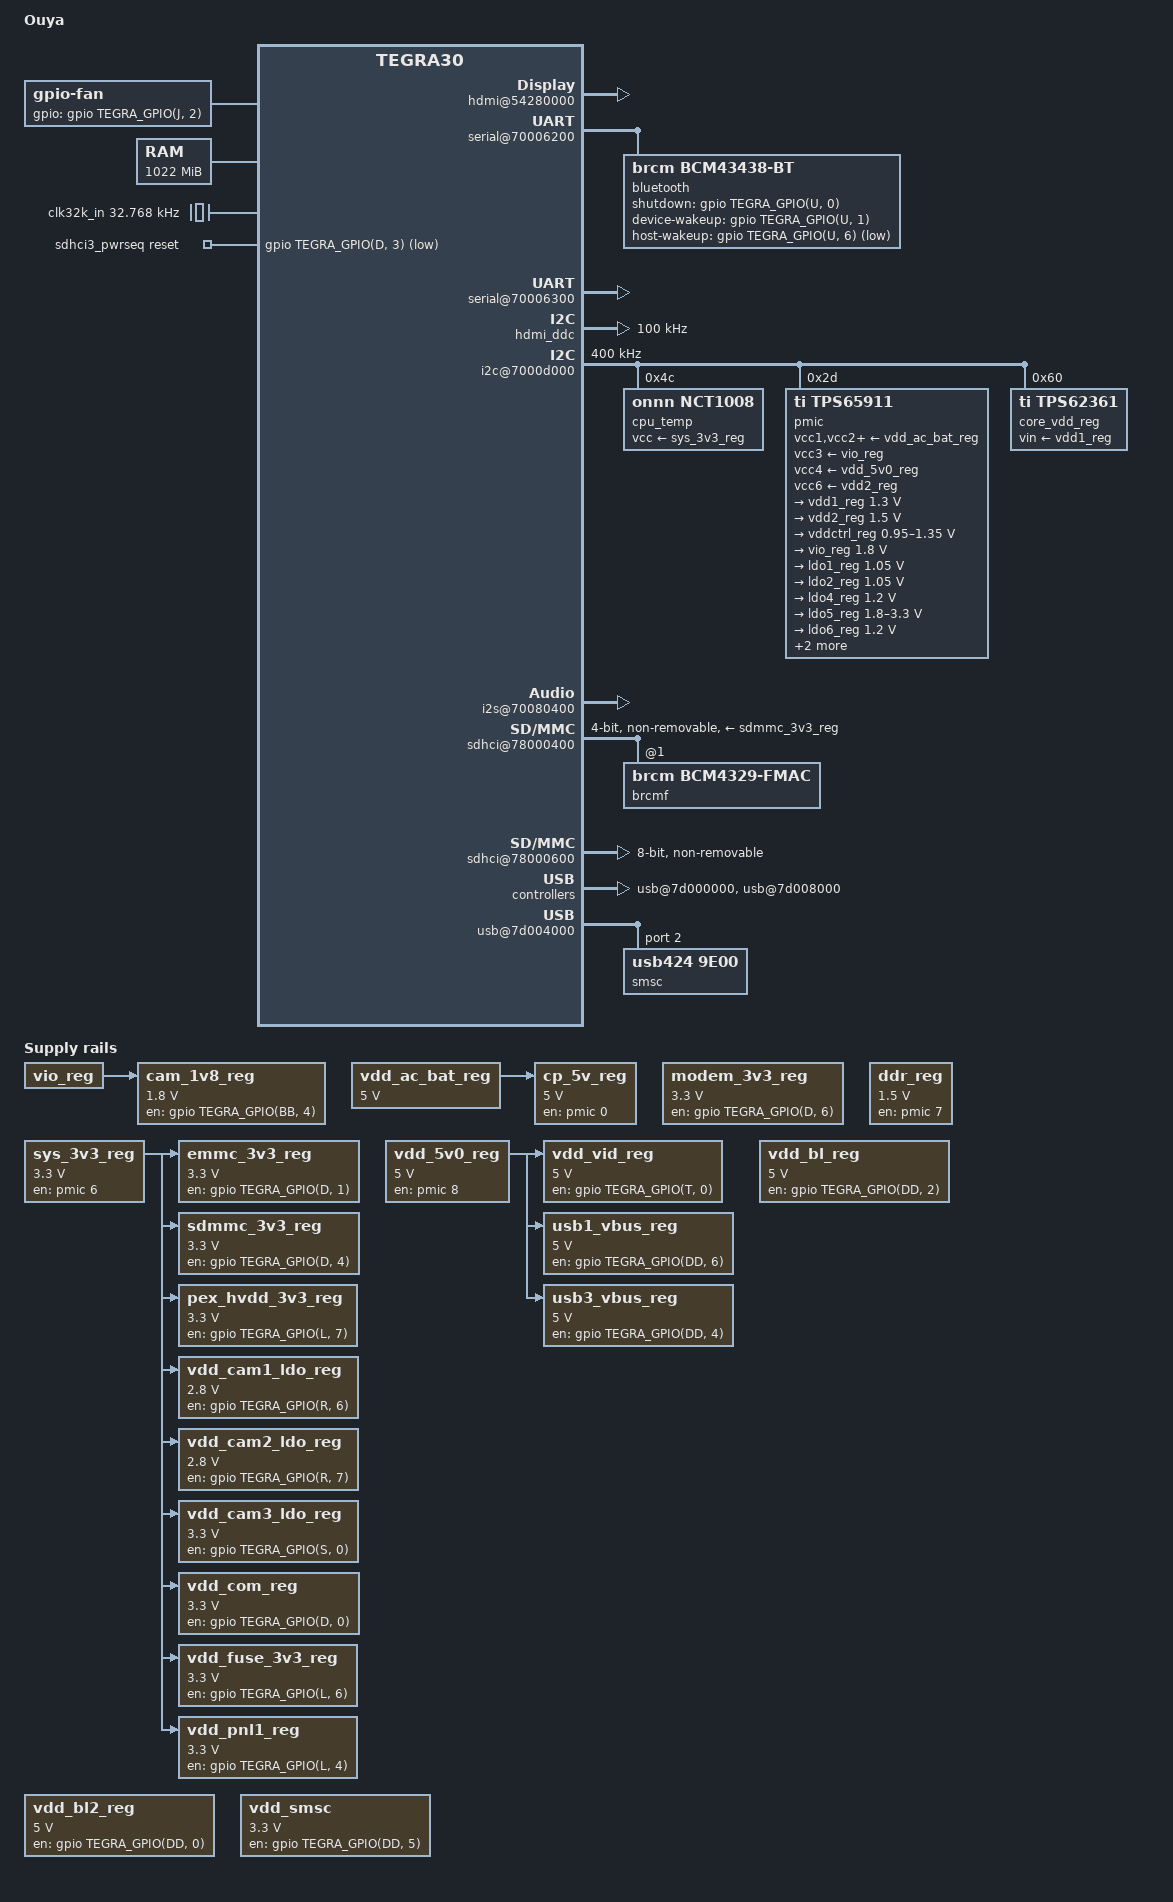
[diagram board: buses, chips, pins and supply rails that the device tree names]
/dts-v1/;

/* This DTS file group supports the OUYA on modern kernels. */
/* The bootloader is extremely basic, and leaves the system in a barely usable state. */
/* This means we have to do everything the bootloader is supposed to do. */

#include <dt-bindings/input/input.h>
#include <dt-bindings/thermal/thermal.h>
#include "tegra30.dtsi"

/ {
	model = "Ouya";
	compatible = "nvidia,ouya", "nvidia,tegra30";

	aliases {
		rtc0 = "/i2c@7000d000/tps65911@2d";
		rtc1 = "/rtc@7000e000";
		serial0 = &uartd;
		serial1 = &uartc;

	};

	chosen {
		stdout-path = "serial0:115200n8";
		bootargs = "earlyprintk gpt gpt_sector=15073279 panic=10 console=ttyS0,115200n8 root=/dev/sda1 rootwait video=HDMI-A-1:1280x720@60 mitigations=off";
	};

	cpus {
		#address-cells = <1>;
		#size-cells = <0>;

		cpu@0 {
			device_type = "cpu";
			compatible = "arm,cortex-a9";
			reg = <0>;
			next-level-cache = <&L2>;
			clock-latency = <65536>; /* two CLK32 periods */
			assigned-clocks = <&tegra_car TEGRA30_CLK_CCLK_G>;
			cpu-supply = <&vddctrl_reg>;
			core-supply = <&core_vdd_reg>;
		};
		cpu@1 {
			next-level-cache = <&L2>;
		};

		cpu@2 {
			next-level-cache = <&L2>;
		};

		cpu@3 {
			next-level-cache = <&L2>;
		};
	};

	fan: gpio_fan {
		compatible = "gpio-fan";
		gpios = <&gpio TEGRA_GPIO(J, 2) GPIO_ACTIVE_HIGH>;
		gpio-fan,speed-map = <0    0
				      4500 1>;
		#cooling-cells = <2>;
	};

	thermal-zones {
		cpu_thermal: cpu-thermal {
			polling-delay = <1000>;
			polling-delay-passive = <250>;

			thermal-sensors = <&cpu_temp 1>;

			trips {
				cpu_alert0: cpu-alert0 {
					temperature = <45000>;
					hysteresis = <5000>;
					type = "active";
				};
				cpu_crit: cpu-crit {
					temperature = <90000>;
					hysteresis = <2000>;
					type = "critical";
				};
			};

			cooling-maps {
				map0 {
					trip = <&cpu_alert0>;
					cooling-device = <&fan 1 THERMAL_NO_LIMIT>;
				};
			};
		};
	};

	L2: cache-controller@50043000 {
	};

	smmu {
		compatible = "nvidia,tegra30-smmu";
		reg = <0x7000f010 0x02c
		       0x7000f1f0 0x010
		       0x7000f228 0x05c>;
		nvidia,#asids = <4>;		/* # of ASIDs */
		dma-window = <0 0x40000000>;	/* IOVA start & length */
		nvidia,ahb = <&ahb>;
	};

	memory@80000000 {
		device_type = "memory";
		reg = <0x80000000 0x3fe00000>;
//		reg = <0x80000000 0x40000000>;
	};

	reserved-memory {
		#address-cells = <1>;
		#size-cells = <1>;
		ranges;

		tf_reserve@7fe00000 {
			reg = <0x7fe00000 0x200000>;
			no-map;
		};
	};

	firmware {
		trusted-foundations {
			compatible = "tlm,trusted-foundations";
			tlm,version-major = <0x2>;
			tlm,version-minor = <0x8>;
		};
	};

	host1x@50000000 {
		hdmi@54280000 {
			status = "okay";
			vdd-supply = <&vdd_vid_reg>;
			pll-supply = <&ldo7_reg>;
			hdmi-supply = <&sys_3v3_reg>;
			nvidia,ddc-i2c-bus = <&hdmi_ddc>;
			nvidia,hpd-gpio = <&gpio TEGRA_GPIO(N, 7) GPIO_ACTIVE_HIGH>;
		};
	};

	gpio: gpio@6000d000 {
		gpio-ranges = <&pinmux 0 0 248>;
		#reset-cells = <1>;
	};

	pinmux@70000868 {
		pinctrl-names = "default";
		pinctrl-0 = <&state_default>;

		state_default: pinmux {
                        clk_32k_out_pa0 {
                                nvidia,pins = "clk_32k_out_pa0";
                                nvidia,function = "blink";
                                nvidia,pull = <TEGRA_PIN_PULL_NONE>;
                                nvidia,tristate = <TEGRA_PIN_DISABLE>;
                                nvidia,enable-input = <TEGRA_PIN_DISABLE>;
                        };
                        uart3_cts_n_pa1 {
                                nvidia,pins = "uart3_cts_n_pa1";
                                nvidia,function = "uartc";
                                nvidia,pull = <TEGRA_PIN_PULL_NONE>;
                                nvidia,tristate = <TEGRA_PIN_DISABLE>;
                                nvidia,enable-input = <TEGRA_PIN_ENABLE>;
                        };
                        dap2_fs_pa2 {
                                nvidia,pins = "dap2_fs_pa2";
                                nvidia,function = "i2s1";
                                nvidia,pull = <TEGRA_PIN_PULL_NONE>;
                                nvidia,tristate = <TEGRA_PIN_DISABLE>;
                                nvidia,enable-input = <TEGRA_PIN_ENABLE>;
                        };
                        dap2_sclk_pa3 {
                                nvidia,pins = "dap2_sclk_pa3";
                                nvidia,function = "i2s1";
                                nvidia,pull = <TEGRA_PIN_PULL_NONE>;
                                nvidia,tristate = <TEGRA_PIN_DISABLE>;
                                nvidia,enable-input = <TEGRA_PIN_ENABLE>;
                        };
                        dap2_din_pa4 {
                                nvidia,pins = "dap2_din_pa4";
                                nvidia,function = "i2s1";
                                nvidia,pull = <TEGRA_PIN_PULL_NONE>;
                                nvidia,tristate = <TEGRA_PIN_DISABLE>;
                                nvidia,enable-input = <TEGRA_PIN_ENABLE>;
                        };
                        dap2_dout_pa5 {
                                nvidia,pins = "dap2_dout_pa5";
                                nvidia,function = "i2s1";
                                nvidia,pull = <TEGRA_PIN_PULL_NONE>;
                                nvidia,tristate = <TEGRA_PIN_DISABLE>;
                                nvidia,enable-input = <TEGRA_PIN_ENABLE>;
                        };
                        sdmmc3_clk_pa6 {
                                nvidia,pins = "sdmmc3_clk_pa6";
                                nvidia,function = "sdmmc3";
                                nvidia,pull = <TEGRA_PIN_PULL_NONE>;
                                nvidia,tristate = <TEGRA_PIN_DISABLE>;
                                nvidia,enable-input = <TEGRA_PIN_ENABLE>;
                        };
                        sdmmc3_cmd_pa7 {
                                nvidia,pins = "sdmmc3_cmd_pa7";
                                nvidia,function = "sdmmc3";
                                nvidia,pull = <TEGRA_PIN_PULL_UP>;
                                nvidia,tristate = <TEGRA_PIN_DISABLE>;
                                nvidia,enable-input = <TEGRA_PIN_ENABLE>;
                        };
                        gmi_a17_pb0 {
                                nvidia,pins = "gmi_a17_pb0";
                                nvidia,function = "spi4";
                                nvidia,pull = <TEGRA_PIN_PULL_NONE>;
                                nvidia,tristate = <TEGRA_PIN_DISABLE>;
                                nvidia,enable-input = <TEGRA_PIN_ENABLE>;
                        };
                        gmi_a18_pb1 {
                                nvidia,pins = "gmi_a18_pb1";
                                nvidia,function = "spi4";
                                nvidia,pull = <TEGRA_PIN_PULL_NONE>;
                                nvidia,tristate = <TEGRA_PIN_DISABLE>;
                                nvidia,enable-input = <TEGRA_PIN_ENABLE>;
                        };
                        lcd_pwr0_pb2 {
                                nvidia,pins = "lcd_pwr0_pb2";
                                nvidia,function = "displaya";
                                nvidia,pull = <TEGRA_PIN_PULL_NONE>;
                                nvidia,tristate = <TEGRA_PIN_DISABLE>;
                                nvidia,enable-input = <TEGRA_PIN_ENABLE>;
                        };
                        lcd_pclk_pb3 {
                                nvidia,pins = "lcd_pclk_pb3";
                                nvidia,function = "displaya";
                                nvidia,pull = <TEGRA_PIN_PULL_NONE>;
                                nvidia,tristate = <TEGRA_PIN_DISABLE>;
                                nvidia,enable-input = <TEGRA_PIN_ENABLE>;
                        };
                        sdmmc3_dat3_pb4 {
                                nvidia,pins = "sdmmc3_dat3_pb4";
                                nvidia,function = "sdmmc3";
                                nvidia,pull = <TEGRA_PIN_PULL_UP>;
                                nvidia,tristate = <TEGRA_PIN_DISABLE>;
                                nvidia,enable-input = <TEGRA_PIN_ENABLE>;
                        };
                        sdmmc3_dat2_pb5 {
                                nvidia,pins = "sdmmc3_dat2_pb5";
                                nvidia,function = "sdmmc3";
                                nvidia,pull = <TEGRA_PIN_PULL_UP>;
                                nvidia,tristate = <TEGRA_PIN_DISABLE>;
                                nvidia,enable-input = <TEGRA_PIN_ENABLE>;
                        };
                        sdmmc3_dat1_pb6 {
                                nvidia,pins = "sdmmc3_dat1_pb6";
                                nvidia,function = "sdmmc3";
                                nvidia,pull = <TEGRA_PIN_PULL_UP>;
                                nvidia,tristate = <TEGRA_PIN_DISABLE>;
                                nvidia,enable-input = <TEGRA_PIN_ENABLE>;
                        };
                        sdmmc3_dat0_pb7 {
                                nvidia,pins = "sdmmc3_dat0_pb7";
                                nvidia,function = "sdmmc3";
                                nvidia,pull = <TEGRA_PIN_PULL_UP>;
                                nvidia,tristate = <TEGRA_PIN_DISABLE>;
                                nvidia,enable-input = <TEGRA_PIN_ENABLE>;
                        };
                        uart3_rts_n_pc0 {
                                nvidia,pins = "uart3_rts_n_pc0";
                                nvidia,function = "uartc";
                                nvidia,pull = <TEGRA_PIN_PULL_NONE>;
                                nvidia,tristate = <TEGRA_PIN_DISABLE>;
                                nvidia,enable-input = <TEGRA_PIN_DISABLE>;
                        };
                        lcd_pwr1_pc1 {
                                nvidia,pins = "lcd_pwr1_pc1";
                                nvidia,function = "displaya";
                                nvidia,pull = <TEGRA_PIN_PULL_NONE>;
                                nvidia,tristate = <TEGRA_PIN_DISABLE>;
                                nvidia,enable-input = <TEGRA_PIN_ENABLE>;
                        };
                        uart2_txd_pc2 {
                                nvidia,pins = "uart2_txd_pc2";
                                nvidia,function = "uartb";
                                nvidia,pull = <TEGRA_PIN_PULL_NONE>;
                                nvidia,tristate = <TEGRA_PIN_DISABLE>;
                                nvidia,enable-input = <TEGRA_PIN_DISABLE>;
                        };
                        uart2_rxd_pc3 {
                                nvidia,pins = "uart2_rxd_pc3";
                                nvidia,function = "uartb";
                                nvidia,pull = <TEGRA_PIN_PULL_NONE>;
                                nvidia,tristate = <TEGRA_PIN_DISABLE>;
                                nvidia,enable-input = <TEGRA_PIN_ENABLE>;
                        };
                        gen1_i2c_scl_pc4 {
                                nvidia,pins = "gen1_i2c_scl_pc4";
                                nvidia,function = "i2c1";
                                nvidia,pull = <TEGRA_PIN_PULL_NONE>;
                                nvidia,tristate = <TEGRA_PIN_DISABLE>;
                                nvidia,enable-input = <TEGRA_PIN_ENABLE>;
                                nvidia,open-drain = <TEGRA_PIN_ENABLE>;
                        };
                        gen1_i2c_sda_pc5 {
                                nvidia,pins = "gen1_i2c_sda_pc5";
                                nvidia,function = "i2c1";
                                nvidia,pull = <TEGRA_PIN_PULL_NONE>;
                                nvidia,tristate = <TEGRA_PIN_DISABLE>;
                                nvidia,enable-input = <TEGRA_PIN_ENABLE>;
                                nvidia,open-drain = <TEGRA_PIN_ENABLE>;
                        };
                        lcd_pwr2_pc6 {
                                nvidia,pins = "lcd_pwr2_pc6";
                                nvidia,function = "displaya";
                                nvidia,pull = <TEGRA_PIN_PULL_NONE>;
                                nvidia,tristate = <TEGRA_PIN_DISABLE>;
                                nvidia,enable-input = <TEGRA_PIN_ENABLE>;
                        };
                        gmi_wp_n_pc7 {
                                nvidia,pins = "gmi_wp_n_pc7";
                                nvidia,function = "gmi";
                                nvidia,pull = <TEGRA_PIN_PULL_NONE>;
                                nvidia,tristate = <TEGRA_PIN_DISABLE>;
                                nvidia,enable-input = <TEGRA_PIN_ENABLE>;
                        };
                        sdmmc3_dat5_pd0 {
                                nvidia,pins = "sdmmc3_dat5_pd0";
                                nvidia,function = "sdmmc3";
                                nvidia,pull = <TEGRA_PIN_PULL_UP>;
                                nvidia,tristate = <TEGRA_PIN_DISABLE>;
                                nvidia,enable-input = <TEGRA_PIN_ENABLE>;
                        };
                        sdmmc3_dat4_pd1 {
                                nvidia,pins = "sdmmc3_dat4_pd1";
                                nvidia,function = "sdmmc3";
                                nvidia,pull = <TEGRA_PIN_PULL_UP>;
                                nvidia,tristate = <TEGRA_PIN_DISABLE>;
                                nvidia,enable-input = <TEGRA_PIN_ENABLE>;
                        };
                        lcd_dc1_pd2 {
                                nvidia,pins = "lcd_dc1_pd2";
                                nvidia,function = "displaya";
                                nvidia,pull = <TEGRA_PIN_PULL_NONE>;
                                nvidia,tristate = <TEGRA_PIN_DISABLE>;
                                nvidia,enable-input = <TEGRA_PIN_ENABLE>;
                        };
                        sdmmc3_dat6_pd3 {
                                nvidia,pins = "sdmmc3_dat6_pd3";
                                nvidia,function = "spdif";
                                nvidia,pull = <TEGRA_PIN_PULL_NONE>;
                                nvidia,tristate = <TEGRA_PIN_DISABLE>;
                                nvidia,enable-input = <TEGRA_PIN_ENABLE>;
                        };
                        sdmmc3_dat7_pd4 {
                                nvidia,pins = "sdmmc3_dat7_pd4";
                                nvidia,function = "spdif";
                                nvidia,pull = <TEGRA_PIN_PULL_NONE>;
                                nvidia,tristate = <TEGRA_PIN_DISABLE>;
                                nvidia,enable-input = <TEGRA_PIN_ENABLE>;
                        };
                        vi_d1_pd5 {
                                nvidia,pins = "vi_d1_pd5";
                                nvidia,function = "sdmmc2";
                                nvidia,pull = <TEGRA_PIN_PULL_NONE>;
                                nvidia,tristate = <TEGRA_PIN_DISABLE>;
                                nvidia,enable-input = <TEGRA_PIN_ENABLE>;
                        };
                        vi_vsync_pd6 {
                                nvidia,pins = "vi_vsync_pd6";
                                nvidia,function = "ddr";
                                nvidia,pull = <TEGRA_PIN_PULL_NONE>;
                                nvidia,tristate = <TEGRA_PIN_DISABLE>;
                                nvidia,enable-input = <TEGRA_PIN_ENABLE>;
                        };
                        vi_hsync_pd7 {
                                nvidia,pins = "vi_hsync_pd7";
                                nvidia,function = "ddr";
                                nvidia,pull = <TEGRA_PIN_PULL_NONE>;
                                nvidia,tristate = <TEGRA_PIN_DISABLE>;
                                nvidia,enable-input = <TEGRA_PIN_ENABLE>;
                        };
                        lcd_d0_pe0 {
                                nvidia,pins = "lcd_d0_pe0";
                                nvidia,function = "displaya";
                                nvidia,pull = <TEGRA_PIN_PULL_NONE>;
                                nvidia,tristate = <TEGRA_PIN_DISABLE>;
                                nvidia,enable-input = <TEGRA_PIN_ENABLE>;
                        };
                        lcd_d1_pe1 {
                                nvidia,pins = "lcd_d1_pe1";
                                nvidia,function = "displaya";
                                nvidia,pull = <TEGRA_PIN_PULL_NONE>;
                                nvidia,tristate = <TEGRA_PIN_DISABLE>;
                                nvidia,enable-input = <TEGRA_PIN_ENABLE>;
                        };
                        lcd_d2_pe2 {
                                nvidia,pins = "lcd_d2_pe2";
                                nvidia,function = "displaya";
                                nvidia,pull = <TEGRA_PIN_PULL_NONE>;
                                nvidia,tristate = <TEGRA_PIN_DISABLE>;
                                nvidia,enable-input = <TEGRA_PIN_ENABLE>;
                        };
                        lcd_d3_pe3 {
                                nvidia,pins = "lcd_d3_pe3";
                                nvidia,function = "displaya";
                                nvidia,pull = <TEGRA_PIN_PULL_NONE>;
                                nvidia,tristate = <TEGRA_PIN_DISABLE>;
                                nvidia,enable-input = <TEGRA_PIN_ENABLE>;
                        };
                        lcd_d4_pe4 {
                                nvidia,pins = "lcd_d4_pe4";
                                nvidia,function = "displaya";
                                nvidia,pull = <TEGRA_PIN_PULL_NONE>;
                                nvidia,tristate = <TEGRA_PIN_DISABLE>;
                                nvidia,enable-input = <TEGRA_PIN_ENABLE>;
                        };
                        lcd_d5_pe5 {
                                nvidia,pins = "lcd_d5_pe5";
                                nvidia,function = "displaya";
                                nvidia,pull = <TEGRA_PIN_PULL_NONE>;
                                nvidia,tristate = <TEGRA_PIN_DISABLE>;
                                nvidia,enable-input = <TEGRA_PIN_ENABLE>;
                        };
                        lcd_d6_pe6 {
                                nvidia,pins = "lcd_d6_pe6";
                                nvidia,function = "displaya";
                                nvidia,pull = <TEGRA_PIN_PULL_NONE>;
                                nvidia,tristate = <TEGRA_PIN_DISABLE>;
                                nvidia,enable-input = <TEGRA_PIN_ENABLE>;
                        };
                        lcd_d7_pe7 {
                                nvidia,pins = "lcd_d7_pe7";
                                nvidia,function = "displaya";
                                nvidia,pull = <TEGRA_PIN_PULL_NONE>;
                                nvidia,tristate = <TEGRA_PIN_DISABLE>;
                                nvidia,enable-input = <TEGRA_PIN_ENABLE>;
                        };
                        lcd_d8_pf0 {
                                nvidia,pins = "lcd_d8_pf0";
                                nvidia,function = "displaya";
                                nvidia,pull = <TEGRA_PIN_PULL_NONE>;
                                nvidia,tristate = <TEGRA_PIN_DISABLE>;
                                nvidia,enable-input = <TEGRA_PIN_ENABLE>;
                        };
                        lcd_d9_pf1 {
                                nvidia,pins = "lcd_d9_pf1";
                                nvidia,function = "displaya";
                                nvidia,pull = <TEGRA_PIN_PULL_NONE>;
                                nvidia,tristate = <TEGRA_PIN_DISABLE>;
                                nvidia,enable-input = <TEGRA_PIN_ENABLE>;
                        };
                        lcd_d10_pf2 {
                                nvidia,pins = "lcd_d10_pf2";
                                nvidia,function = "displaya";
                                nvidia,pull = <TEGRA_PIN_PULL_NONE>;
                                nvidia,tristate = <TEGRA_PIN_DISABLE>;
                                nvidia,enable-input = <TEGRA_PIN_ENABLE>;
                        };
                        lcd_d11_pf3 {
                                nvidia,pins = "lcd_d11_pf3";
                                nvidia,function = "displaya";
                                nvidia,pull = <TEGRA_PIN_PULL_NONE>;
                                nvidia,tristate = <TEGRA_PIN_DISABLE>;
                                nvidia,enable-input = <TEGRA_PIN_ENABLE>;
                        };
                        lcd_d12_pf4 {
                                nvidia,pins = "lcd_d12_pf4";
                                nvidia,function = "displaya";
                                nvidia,pull = <TEGRA_PIN_PULL_NONE>;
                                nvidia,tristate = <TEGRA_PIN_DISABLE>;
                                nvidia,enable-input = <TEGRA_PIN_ENABLE>;
                        };
                        lcd_d13_pf5 {
                                nvidia,pins = "lcd_d13_pf5";
                                nvidia,function = "displaya";
                                nvidia,pull = <TEGRA_PIN_PULL_NONE>;
                                nvidia,tristate = <TEGRA_PIN_DISABLE>;
                                nvidia,enable-input = <TEGRA_PIN_ENABLE>;
                        };
                        lcd_d14_pf6 {
                                nvidia,pins = "lcd_d14_pf6";
                                nvidia,function = "displaya";
                                nvidia,pull = <TEGRA_PIN_PULL_NONE>;
                                nvidia,tristate = <TEGRA_PIN_DISABLE>;
                                nvidia,enable-input = <TEGRA_PIN_ENABLE>;
                        };
                        lcd_d15_pf7 {
                                nvidia,pins = "lcd_d15_pf7";
                                nvidia,function = "displaya";
                                nvidia,pull = <TEGRA_PIN_PULL_NONE>;
                                nvidia,tristate = <TEGRA_PIN_DISABLE>;
                                nvidia,enable-input = <TEGRA_PIN_ENABLE>;
                        };
                        gmi_ad0_pg0 {
                                nvidia,pins = "gmi_ad0_pg0";
                                nvidia,function = "nand";
                                nvidia,pull = <TEGRA_PIN_PULL_NONE>;
                                nvidia,tristate = <TEGRA_PIN_ENABLE>;
                                nvidia,enable-input = <TEGRA_PIN_DISABLE>;
                        };
                        gmi_ad1_pg1 {
                                nvidia,pins = "gmi_ad1_pg1";
                                nvidia,function = "nand";
                                nvidia,pull = <TEGRA_PIN_PULL_NONE>;
                                nvidia,tristate = <TEGRA_PIN_ENABLE>;
                                nvidia,enable-input = <TEGRA_PIN_DISABLE>;
                        };
                        gmi_ad2_pg2 {
                                nvidia,pins = "gmi_ad2_pg2";
                                nvidia,function = "nand";
                                nvidia,pull = <TEGRA_PIN_PULL_NONE>;
                                nvidia,tristate = <TEGRA_PIN_ENABLE>;
                                nvidia,enable-input = <TEGRA_PIN_DISABLE>;
                        };
                        gmi_ad3_pg3 {
                                nvidia,pins = "gmi_ad3_pg3";
                                nvidia,function = "nand";
                                nvidia,pull = <TEGRA_PIN_PULL_NONE>;
                                nvidia,tristate = <TEGRA_PIN_ENABLE>;
                                nvidia,enable-input = <TEGRA_PIN_DISABLE>;
                        };
                        gmi_ad4_pg4 {
                                nvidia,pins = "gmi_ad4_pg4";
                                nvidia,function = "nand";
                                nvidia,pull = <TEGRA_PIN_PULL_NONE>;
                                nvidia,tristate = <TEGRA_PIN_ENABLE>;
                                nvidia,enable-input = <TEGRA_PIN_DISABLE>;
                        };
                        gmi_ad5_pg5 {
                                nvidia,pins = "gmi_ad5_pg5";
                                nvidia,function = "nand";
                                nvidia,pull = <TEGRA_PIN_PULL_NONE>;
                                nvidia,tristate = <TEGRA_PIN_ENABLE>;
                                nvidia,enable-input = <TEGRA_PIN_DISABLE>;
                        };
                        gmi_ad6_pg6 {
                                nvidia,pins = "gmi_ad6_pg6";
                                nvidia,function = "nand";
                                nvidia,pull = <TEGRA_PIN_PULL_NONE>;
                                nvidia,tristate = <TEGRA_PIN_ENABLE>;
                                nvidia,enable-input = <TEGRA_PIN_DISABLE>;
                        };
                        gmi_ad7_pg7 {
                                nvidia,pins = "gmi_ad7_pg7";
                                nvidia,function = "nand";
                                nvidia,pull = <TEGRA_PIN_PULL_NONE>;
                                nvidia,tristate = <TEGRA_PIN_ENABLE>;
                                nvidia,enable-input = <TEGRA_PIN_DISABLE>;
                        };
                        gmi_ad8_ph0 {
                                nvidia,pins = "gmi_ad8_ph0";
                                nvidia,function = "pwm0";
                                nvidia,pull = <TEGRA_PIN_PULL_NONE>;
                                nvidia,tristate = <TEGRA_PIN_DISABLE>;
                                nvidia,enable-input = <TEGRA_PIN_DISABLE>;
                        };
                        gmi_ad9_ph1 {
                                nvidia,pins = "gmi_ad9_ph1";
                                nvidia,function = "pwm1";
                                nvidia,pull = <TEGRA_PIN_PULL_NONE>;
                                nvidia,tristate = <TEGRA_PIN_ENABLE>;
                                nvidia,enable-input = <TEGRA_PIN_DISABLE>;
                        };
                        gmi_ad10_ph2 {
                                nvidia,pins = "gmi_ad10_ph2";
                                nvidia,function = "nand";
                                nvidia,pull = <TEGRA_PIN_PULL_NONE>;
                                nvidia,tristate = <TEGRA_PIN_DISABLE>;
                                nvidia,enable-input = <TEGRA_PIN_DISABLE>;
                        };
                        gmi_ad11_ph3 {
                                nvidia,pins = "gmi_ad11_ph3";
                                nvidia,function = "nand";
                                nvidia,pull = <TEGRA_PIN_PULL_NONE>;
                                nvidia,tristate = <TEGRA_PIN_ENABLE>;
                                nvidia,enable-input = <TEGRA_PIN_DISABLE>;
                        };
                        gmi_ad12_ph4 {
                                nvidia,pins = "gmi_ad12_ph4";
                                nvidia,function = "nand";
                                nvidia,pull = <TEGRA_PIN_PULL_UP>;
                                nvidia,tristate = <TEGRA_PIN_DISABLE>;
                                nvidia,enable-input = <TEGRA_PIN_ENABLE>;
                        };
                        gmi_ad13_ph5 {
                                nvidia,pins = "gmi_ad13_ph5";
                                nvidia,function = "nand";
                                nvidia,pull = <TEGRA_PIN_PULL_UP>;
                                nvidia,tristate = <TEGRA_PIN_ENABLE>;
                                nvidia,enable-input = <TEGRA_PIN_ENABLE>;
                        };
                        gmi_ad14_ph6 {
                                nvidia,pins = "gmi_ad14_ph6";
                                nvidia,function = "nand";
                                nvidia,pull = <TEGRA_PIN_PULL_NONE>;
                                nvidia,tristate = <TEGRA_PIN_DISABLE>;
                                nvidia,enable-input = <TEGRA_PIN_DISABLE>;
                        };
                        gmi_wr_n_pi0 {
                                nvidia,pins = "gmi_wr_n_pi0";
                                nvidia,function = "nand";
                                nvidia,pull = <TEGRA_PIN_PULL_NONE>;
                                nvidia,tristate = <TEGRA_PIN_ENABLE>;
                                nvidia,enable-input = <TEGRA_PIN_DISABLE>;
                        };
                        gmi_oe_n_pi1 {
                                nvidia,pins = "gmi_oe_n_pi1";
                                nvidia,function = "nand";
                                nvidia,pull = <TEGRA_PIN_PULL_NONE>;
                                nvidia,tristate = <TEGRA_PIN_ENABLE>;
                                nvidia,enable-input = <TEGRA_PIN_DISABLE>;
                        };
                        gmi_dqs_pi2 {
                                nvidia,pins = "gmi_dqs_pi2";
                                nvidia,function = "nand";
                                nvidia,pull = <TEGRA_PIN_PULL_NONE>;
                                nvidia,tristate = <TEGRA_PIN_ENABLE>;
                                nvidia,enable-input = <TEGRA_PIN_DISABLE>;
                        };
                        gmi_iordy_pi5 {
                                nvidia,pins = "gmi_iordy_pi5";
                                nvidia,function = "rsvd1";
                                nvidia,pull = <TEGRA_PIN_PULL_UP>;
                                nvidia,tristate = <TEGRA_PIN_DISABLE>;
                                nvidia,enable-input = <TEGRA_PIN_ENABLE>;
                        };
                        gmi_cs7_n_pi6 {
                                nvidia,pins = "gmi_cs7_n_pi6";
                                nvidia,function = "nand";
                                nvidia,pull = <TEGRA_PIN_PULL_UP>;
                                nvidia,tristate = <TEGRA_PIN_ENABLE>;
                                nvidia,enable-input = <TEGRA_PIN_ENABLE>;
                        };
                        gmi_wait_pi7 {
                                nvidia,pins = "gmi_wait_pi7";
                                nvidia,function = "nand";
                                nvidia,pull = <TEGRA_PIN_PULL_UP>;
                                nvidia,tristate = <TEGRA_PIN_ENABLE>;
                                nvidia,enable-input = <TEGRA_PIN_DISABLE>;
                        };
                        lcd_de_pj1 {
                                nvidia,pins = "lcd_de_pj1";
                                nvidia,function = "displaya";
                                nvidia,pull = <TEGRA_PIN_PULL_NONE>;
                                nvidia,tristate = <TEGRA_PIN_DISABLE>;
                                nvidia,enable-input = <TEGRA_PIN_ENABLE>;
                        };
			gmi_cs1_n_pj2 {
                                nvidia,pins = "gmi_cs1_n_pj2";
                                nvidia,function = "rsvd1";
                                nvidia,pull = <TEGRA_PIN_PULL_NONE>;
                                nvidia,tristate = <TEGRA_PIN_DISABLE>;
                                nvidia,enable-input = <TEGRA_PIN_DISABLE>;
                        };
                        lcd_hsync_pj3 {
                                nvidia,pins = "lcd_hsync_pj3";
                                nvidia,function = "displaya";
                                nvidia,pull = <TEGRA_PIN_PULL_NONE>;
                                nvidia,tristate = <TEGRA_PIN_DISABLE>;
                                nvidia,enable-input = <TEGRA_PIN_ENABLE>;
                        };
                        lcd_vsync_pj4 {
                                nvidia,pins = "lcd_vsync_pj4";
                                nvidia,function = "displaya";
                                nvidia,pull = <TEGRA_PIN_PULL_NONE>;
                                nvidia,tristate = <TEGRA_PIN_DISABLE>;
                                nvidia,enable-input = <TEGRA_PIN_ENABLE>;
                        };
                        uart2_cts_n_pj5 {
                                nvidia,pins = "uart2_cts_n_pj5";
                                nvidia,function = "uartb";
                                nvidia,pull = <TEGRA_PIN_PULL_NONE>;
                                nvidia,tristate = <TEGRA_PIN_DISABLE>;
                                nvidia,enable-input = <TEGRA_PIN_ENABLE>;
                        };
                        uart2_rts_n_pj6 {
                                nvidia,pins = "uart2_rts_n_pj6";
                                nvidia,function = "uartb";
                                nvidia,pull = <TEGRA_PIN_PULL_NONE>;
                                nvidia,tristate = <TEGRA_PIN_DISABLE>;
                                nvidia,enable-input = <TEGRA_PIN_DISABLE>;
                        };
                        gmi_a16_pj7 {
                                nvidia,pins = "gmi_a16_pj7";
                                nvidia,function = "spi4";
                                nvidia,pull = <TEGRA_PIN_PULL_NONE>;
                                nvidia,tristate = <TEGRA_PIN_DISABLE>;
                                nvidia,enable-input = <TEGRA_PIN_ENABLE>;
                        };
                        gmi_adv_n_pk0 {
                                nvidia,pins = "gmi_adv_n_pk0";
                                nvidia,function = "nand";
                                nvidia,pull = <TEGRA_PIN_PULL_NONE>;
                                nvidia,tristate = <TEGRA_PIN_ENABLE>;
                                nvidia,enable-input = <TEGRA_PIN_DISABLE>;
                        };
                        gmi_clk_pk1 {
                                nvidia,pins = "gmi_clk_pk1";
                                nvidia,function = "nand";
                                nvidia,pull = <TEGRA_PIN_PULL_NONE>;
                                nvidia,tristate = <TEGRA_PIN_ENABLE>;
                                nvidia,enable-input = <TEGRA_PIN_DISABLE>;
                        };
                        gmi_cs2_n_pk3 {
                                nvidia,pins = "gmi_cs2_n_pk3";
                                nvidia,function = "rsvd1";
                                nvidia,pull = <TEGRA_PIN_PULL_UP>;
                                nvidia,tristate = <TEGRA_PIN_DISABLE>;
                                nvidia,enable-input = <TEGRA_PIN_ENABLE>;
                        };
                        gmi_cs3_n_pk4 {
                                nvidia,pins = "gmi_cs3_n_pk4";
                                nvidia,function = "nand";
                                nvidia,pull = <TEGRA_PIN_PULL_NONE>;
                                nvidia,tristate = <TEGRA_PIN_ENABLE>;
                                nvidia,enable-input = <TEGRA_PIN_DISABLE>;
                        };
                        spdif_out_pk5 {
                                nvidia,pins = "spdif_out_pk5";
                                nvidia,function = "spdif";
                                nvidia,pull = <TEGRA_PIN_PULL_NONE>;
                                nvidia,tristate = <TEGRA_PIN_DISABLE>;
                                nvidia,enable-input = <TEGRA_PIN_DISABLE>;
                        };
                        spdif_in_pk6 {
                                nvidia,pins = "spdif_in_pk6";
                                nvidia,function = "spdif";
                                nvidia,pull = <TEGRA_PIN_PULL_NONE>;
                                nvidia,tristate = <TEGRA_PIN_DISABLE>;
                                nvidia,enable-input = <TEGRA_PIN_ENABLE>;
                        };
                        gmi_a19_pk7 {
                                nvidia,pins = "gmi_a19_pk7";
                                nvidia,function = "spi4";
                                nvidia,pull = <TEGRA_PIN_PULL_NONE>;
                                nvidia,tristate = <TEGRA_PIN_DISABLE>;
                                nvidia,enable-input = <TEGRA_PIN_ENABLE>;
                        };
                        vi_d2_pl0 {
                                nvidia,pins = "vi_d2_pl0";
                                nvidia,function = "sdmmc2";
                                nvidia,pull = <TEGRA_PIN_PULL_NONE>;
                                nvidia,tristate = <TEGRA_PIN_DISABLE>;
                                nvidia,enable-input = <TEGRA_PIN_ENABLE>;
                        };
                        vi_d3_pl1 {
                                nvidia,pins = "vi_d3_pl1";
                                nvidia,function = "sdmmc2";
                                nvidia,pull = <TEGRA_PIN_PULL_NONE>;
                                nvidia,tristate = <TEGRA_PIN_DISABLE>;
                                nvidia,enable-input = <TEGRA_PIN_ENABLE>;
                        };
                        vi_d4_pl2 {
                                nvidia,pins = "vi_d4_pl2";
                                nvidia,function = "vi";
                                nvidia,pull = <TEGRA_PIN_PULL_NONE>;
                                nvidia,tristate = <TEGRA_PIN_DISABLE>;
                                nvidia,enable-input = <TEGRA_PIN_DISABLE>;
                        };
                        vi_d5_pl3 {
                                nvidia,pins = "vi_d5_pl3";
                                nvidia,function = "sdmmc2";
                                nvidia,pull = <TEGRA_PIN_PULL_NONE>;
                                nvidia,tristate = <TEGRA_PIN_DISABLE>;
                                nvidia,enable-input = <TEGRA_PIN_ENABLE>;
                        };
                        vi_d6_pl4 {
                                nvidia,pins = "vi_d6_pl4";
                                nvidia,function = "vi";
                                nvidia,pull = <TEGRA_PIN_PULL_NONE>;
                                nvidia,tristate = <TEGRA_PIN_DISABLE>;
                                nvidia,enable-input = <TEGRA_PIN_DISABLE>;
                        };
                        vi_d7_pl5 {
                                nvidia,pins = "vi_d7_pl5";
                                nvidia,function = "sdmmc2";
                                nvidia,pull = <TEGRA_PIN_PULL_NONE>;
                                nvidia,tristate = <TEGRA_PIN_DISABLE>;
                                nvidia,enable-input = <TEGRA_PIN_ENABLE>;
                        };
                        vi_d8_pl6 {
                                nvidia,pins = "vi_d8_pl6";
                                nvidia,function = "sdmmc2";
                                nvidia,pull = <TEGRA_PIN_PULL_NONE>;
                                nvidia,tristate = <TEGRA_PIN_DISABLE>;
                                nvidia,enable-input = <TEGRA_PIN_ENABLE>;
                        };
                        vi_d9_pl7 {
                                nvidia,pins = "vi_d9_pl7";
                                nvidia,function = "sdmmc2";
                                nvidia,pull = <TEGRA_PIN_PULL_NONE>;
                                nvidia,tristate = <TEGRA_PIN_DISABLE>;
                                nvidia,enable-input = <TEGRA_PIN_ENABLE>;
                        };
                        lcd_d16_pm0 {
                                nvidia,pins = "lcd_d16_pm0";
                                nvidia,function = "displaya";
                                nvidia,pull = <TEGRA_PIN_PULL_NONE>;
                                nvidia,tristate = <TEGRA_PIN_DISABLE>;
                                nvidia,enable-input = <TEGRA_PIN_ENABLE>;
                        };
                        lcd_d17_pm1 {
                                nvidia,pins = "lcd_d17_pm1";
                                nvidia,function = "displaya";
                                nvidia,pull = <TEGRA_PIN_PULL_NONE>;
                                nvidia,tristate = <TEGRA_PIN_DISABLE>;
                                nvidia,enable-input = <TEGRA_PIN_ENABLE>;
                        };
                        lcd_d18_pm2 {
                                nvidia,pins = "lcd_d18_pm2";
                                nvidia,function = "displaya";
                                nvidia,pull = <TEGRA_PIN_PULL_NONE>;
                                nvidia,tristate = <TEGRA_PIN_DISABLE>;
                                nvidia,enable-input = <TEGRA_PIN_ENABLE>;
                        };
                        lcd_d19_pm3 {
                                nvidia,pins = "lcd_d19_pm3";
                                nvidia,function = "displaya";
                                nvidia,pull = <TEGRA_PIN_PULL_NONE>;
                                nvidia,tristate = <TEGRA_PIN_DISABLE>;
                                nvidia,enable-input = <TEGRA_PIN_ENABLE>;
                        };
                        lcd_d20_pm4 {
                                nvidia,pins = "lcd_d20_pm4";
                                nvidia,function = "displaya";
                                nvidia,pull = <TEGRA_PIN_PULL_NONE>;
                                nvidia,tristate = <TEGRA_PIN_DISABLE>;
                                nvidia,enable-input = <TEGRA_PIN_ENABLE>;
                        };
                        lcd_d21_pm5 {
                                nvidia,pins = "lcd_d21_pm5";
                                nvidia,function = "displaya";
                                nvidia,pull = <TEGRA_PIN_PULL_NONE>;
                                nvidia,tristate = <TEGRA_PIN_DISABLE>;
                                nvidia,enable-input = <TEGRA_PIN_ENABLE>;
                        };
                        lcd_d22_pm6 {
                                nvidia,pins = "lcd_d22_pm6";
                                nvidia,function = "displaya";
                                nvidia,pull = <TEGRA_PIN_PULL_NONE>;
                                nvidia,tristate = <TEGRA_PIN_DISABLE>;
                                nvidia,enable-input = <TEGRA_PIN_ENABLE>;
                        };
                        lcd_d23_pm7 {
                                nvidia,pins = "lcd_d23_pm7";
                                nvidia,function = "displaya";
                                nvidia,pull = <TEGRA_PIN_PULL_NONE>;
                                nvidia,tristate = <TEGRA_PIN_DISABLE>;
                                nvidia,enable-input = <TEGRA_PIN_ENABLE>;
                        };
                        dap1_fs_pn0 {
                                nvidia,pins = "dap1_fs_pn0";
                                nvidia,function = "i2s0";
                                nvidia,pull = <TEGRA_PIN_PULL_NONE>;
                                nvidia,tristate = <TEGRA_PIN_DISABLE>;
                                nvidia,enable-input = <TEGRA_PIN_ENABLE>;
                        };
                        dap1_din_pn1 {
                                nvidia,pins = "dap1_din_pn1";
                                nvidia,function = "i2s0";
                                nvidia,pull = <TEGRA_PIN_PULL_NONE>;
                                nvidia,tristate = <TEGRA_PIN_DISABLE>;
                                nvidia,enable-input = <TEGRA_PIN_ENABLE>;
                        };
                        dap1_dout_pn2 {
                                nvidia,pins = "dap1_dout_pn2";
                                nvidia,function = "i2s0";
                                nvidia,pull = <TEGRA_PIN_PULL_NONE>;
                                nvidia,tristate = <TEGRA_PIN_DISABLE>;
                                nvidia,enable-input = <TEGRA_PIN_ENABLE>;
                        };
                        dap1_sclk_pn3 {
                                nvidia,pins = "dap1_sclk_pn3";
                                nvidia,function = "i2s0";
                                nvidia,pull = <TEGRA_PIN_PULL_NONE>;
                                nvidia,tristate = <TEGRA_PIN_DISABLE>;
                                nvidia,enable-input = <TEGRA_PIN_ENABLE>;
                        };
                        lcd_cs0_n_pn4 {
                                nvidia,pins = "lcd_cs0_n_pn4";
                                nvidia,function = "displaya";
                                nvidia,pull = <TEGRA_PIN_PULL_NONE>;
                                nvidia,tristate = <TEGRA_PIN_DISABLE>;
                                nvidia,enable-input = <TEGRA_PIN_ENABLE>;
                        };
                        lcd_sdout_pn5 {
                                nvidia,pins = "lcd_sdout_pn5";
                                nvidia,function = "displaya";
                                nvidia,pull = <TEGRA_PIN_PULL_NONE>;
                                nvidia,tristate = <TEGRA_PIN_DISABLE>;
                                nvidia,enable-input = <TEGRA_PIN_ENABLE>;
                        };
                        lcd_dc0_pn6 {
                                nvidia,pins = "lcd_dc0_pn6";
                                nvidia,function = "displaya";
                                nvidia,pull = <TEGRA_PIN_PULL_NONE>;
                                nvidia,tristate = <TEGRA_PIN_DISABLE>;
                                nvidia,enable-input = <TEGRA_PIN_ENABLE>;
                        };
                        hdmi_int_pn7 {
                                nvidia,pins = "hdmi_int_pn7";
                                nvidia,function = "hdmi";
                                nvidia,pull = <TEGRA_PIN_PULL_NONE>;
                                nvidia,tristate = <TEGRA_PIN_ENABLE>;
                                nvidia,enable-input = <TEGRA_PIN_ENABLE>;
                        };
                        ulpi_data7_po0 {
                                nvidia,pins = "ulpi_data7_po0";
                                nvidia,function = "uarta";
                                nvidia,pull = <TEGRA_PIN_PULL_NONE>;
                                nvidia,tristate = <TEGRA_PIN_DISABLE>;
                                nvidia,enable-input = <TEGRA_PIN_DISABLE>;
                        };
                        ulpi_data0_po1 {
                                nvidia,pins = "ulpi_data0_po1";
                                nvidia,function = "uarta";
                                nvidia,pull = <TEGRA_PIN_PULL_NONE>;
                                nvidia,tristate = <TEGRA_PIN_DISABLE>;
                                nvidia,enable-input = <TEGRA_PIN_DISABLE>;
                        };
                        ulpi_data1_po2 {
                                nvidia,pins = "ulpi_data1_po2";
                                nvidia,function = "uarta";
                                nvidia,pull = <TEGRA_PIN_PULL_NONE>;
                                nvidia,tristate = <TEGRA_PIN_DISABLE>;
                                nvidia,enable-input = <TEGRA_PIN_ENABLE>;
                        };
                        ulpi_data2_po3 {
                                nvidia,pins = "ulpi_data2_po3";
                                nvidia,function = "uarta";
                                nvidia,pull = <TEGRA_PIN_PULL_NONE>;
                                nvidia,tristate = <TEGRA_PIN_DISABLE>;
                                nvidia,enable-input = <TEGRA_PIN_ENABLE>;
                        };
                        ulpi_data3_po4 {
                                nvidia,pins = "ulpi_data3_po4";
                                nvidia,function = "uarta";
                                nvidia,pull = <TEGRA_PIN_PULL_NONE>;
                                nvidia,tristate = <TEGRA_PIN_DISABLE>;
                                nvidia,enable-input = <TEGRA_PIN_ENABLE>;
                        };
                        ulpi_data4_po5 {
                                nvidia,pins = "ulpi_data4_po5";
                                nvidia,function = "uarta";
                                nvidia,pull = <TEGRA_PIN_PULL_NONE>;
                                nvidia,tristate = <TEGRA_PIN_DISABLE>;
                                nvidia,enable-input = <TEGRA_PIN_ENABLE>;
                        };
                        ulpi_data5_po6 {
                                nvidia,pins = "ulpi_data5_po6";
                                nvidia,function = "uarta";
                                nvidia,pull = <TEGRA_PIN_PULL_NONE>;
                                nvidia,tristate = <TEGRA_PIN_DISABLE>;
                                nvidia,enable-input = <TEGRA_PIN_ENABLE>;
                        };
                        ulpi_data6_po7 {
                                nvidia,pins = "ulpi_data6_po7";
                                nvidia,function = "uarta";
                                nvidia,pull = <TEGRA_PIN_PULL_NONE>;
                                nvidia,tristate = <TEGRA_PIN_DISABLE>;
                                nvidia,enable-input = <TEGRA_PIN_ENABLE>;
                        };
                        dap3_fs_pp0 {
                                nvidia,pins = "dap3_fs_pp0";
                                nvidia,function = "i2s2";
                                nvidia,pull = <TEGRA_PIN_PULL_NONE>;
                                nvidia,tristate = <TEGRA_PIN_DISABLE>;
                                nvidia,enable-input = <TEGRA_PIN_ENABLE>;
                        };
                        dap3_din_pp1 {
                                nvidia,pins = "dap3_din_pp1";
                                nvidia,function = "i2s2";
                                nvidia,pull = <TEGRA_PIN_PULL_NONE>;
                                nvidia,tristate = <TEGRA_PIN_DISABLE>;
                                nvidia,enable-input = <TEGRA_PIN_ENABLE>;
                        };
                        dap3_dout_pp2 {
                                nvidia,pins = "dap3_dout_pp2";
                                nvidia,function = "i2s2";
                                nvidia,pull = <TEGRA_PIN_PULL_NONE>;
                                nvidia,tristate = <TEGRA_PIN_DISABLE>;
                                nvidia,enable-input = <TEGRA_PIN_ENABLE>;
                        };
                        dap3_sclk_pp3 {
                                nvidia,pins = "dap3_sclk_pp3";
                                nvidia,function = "i2s2";
                                nvidia,pull = <TEGRA_PIN_PULL_NONE>;
                                nvidia,tristate = <TEGRA_PIN_DISABLE>;
                                nvidia,enable-input = <TEGRA_PIN_ENABLE>;
                        };
                        dap4_fs_pp4 {
                                nvidia,pins = "dap4_fs_pp4";
                                nvidia,function = "i2s3";
                                nvidia,pull = <TEGRA_PIN_PULL_NONE>;
                                nvidia,tristate = <TEGRA_PIN_DISABLE>;
                                nvidia,enable-input = <TEGRA_PIN_ENABLE>;
                        };
                        dap4_din_pp5 {
                                nvidia,pins = "dap4_din_pp5";
                                nvidia,function = "i2s3";
                                nvidia,pull = <TEGRA_PIN_PULL_NONE>;
                                nvidia,tristate = <TEGRA_PIN_DISABLE>;
                                nvidia,enable-input = <TEGRA_PIN_ENABLE>;
                        };
                        dap4_dout_pp6 {
                                nvidia,pins = "dap4_dout_pp6";
                                nvidia,function = "i2s3";
                                nvidia,pull = <TEGRA_PIN_PULL_NONE>;
                                nvidia,tristate = <TEGRA_PIN_DISABLE>;
                                nvidia,enable-input = <TEGRA_PIN_ENABLE>;
                        };
                        dap4_sclk_pp7 {
                                nvidia,pins = "dap4_sclk_pp7";
                                nvidia,function = "i2s3";
                                nvidia,pull = <TEGRA_PIN_PULL_NONE>;
                                nvidia,tristate = <TEGRA_PIN_DISABLE>;
                                nvidia,enable-input = <TEGRA_PIN_ENABLE>;
                        };
                        kb_col0_pq0 {
                                nvidia,pins = "kb_col0_pq0";
                                nvidia,function = "kbc";
                                nvidia,pull = <TEGRA_PIN_PULL_UP>;
                                nvidia,tristate = <TEGRA_PIN_DISABLE>;
                                nvidia,enable-input = <TEGRA_PIN_ENABLE>;
                        };
                        kb_col1_pq1 {
                                nvidia,pins = "kb_col1_pq1";
                                nvidia,function = "kbc";
                                nvidia,pull = <TEGRA_PIN_PULL_UP>;
                                nvidia,tristate = <TEGRA_PIN_DISABLE>;
                                nvidia,enable-input = <TEGRA_PIN_ENABLE>;
                        };
                        kb_col2_pq2 {
                                nvidia,pins = "kb_col2_pq2";
                                nvidia,function = "kbc";
                                nvidia,pull = <TEGRA_PIN_PULL_UP>;
                                nvidia,tristate = <TEGRA_PIN_DISABLE>;
                                nvidia,enable-input = <TEGRA_PIN_ENABLE>;
                        };
                        kb_col3_pq3 {
                                nvidia,pins = "kb_col3_pq3";
                                nvidia,function = "kbc";
                                nvidia,pull = <TEGRA_PIN_PULL_UP>;
                                nvidia,tristate = <TEGRA_PIN_DISABLE>;
                                nvidia,enable-input = <TEGRA_PIN_ENABLE>;
                        };
                        kb_col4_pq4 {
                                nvidia,pins = "kb_col4_pq4";
                                nvidia,function = "kbc";
                                nvidia,pull = <TEGRA_PIN_PULL_UP>;
                                nvidia,tristate = <TEGRA_PIN_DISABLE>;
                                nvidia,enable-input = <TEGRA_PIN_ENABLE>;
                        };
                        kb_col5_pq5 {
                                nvidia,pins = "kb_col5_pq5";
                                nvidia,function = "kbc";
                                nvidia,pull = <TEGRA_PIN_PULL_UP>;
                                nvidia,tristate = <TEGRA_PIN_DISABLE>;
                                nvidia,enable-input = <TEGRA_PIN_ENABLE>;
                        };
                        kb_col6_pq6 {
                                nvidia,pins = "kb_col6_pq6";
                                nvidia,function = "kbc";
                                nvidia,pull = <TEGRA_PIN_PULL_UP>;
                                nvidia,tristate = <TEGRA_PIN_DISABLE>;
                                nvidia,enable-input = <TEGRA_PIN_ENABLE>;
                        };
                        kb_col7_pq7 {
                                nvidia,pins = "kb_col7_pq7";
                                nvidia,function = "kbc";
                                nvidia,pull = <TEGRA_PIN_PULL_UP>;
                                nvidia,tristate = <TEGRA_PIN_DISABLE>;
                                nvidia,enable-input = <TEGRA_PIN_ENABLE>;
                        };
                        kb_row0_pr0 {
                                nvidia,pins = "kb_row0_pr0";
                                nvidia,function = "kbc";
                                nvidia,pull = <TEGRA_PIN_PULL_UP>;
                                nvidia,tristate = <TEGRA_PIN_DISABLE>;
                                nvidia,enable-input = <TEGRA_PIN_ENABLE>;
                        };
                        kb_row1_pr1 {
                                nvidia,pins = "kb_row1_pr1";
                                nvidia,function = "kbc";
                                nvidia,pull = <TEGRA_PIN_PULL_UP>;
                                nvidia,tristate = <TEGRA_PIN_DISABLE>;
                                nvidia,enable-input = <TEGRA_PIN_ENABLE>;
                        };
                        kb_row2_pr2 {
                                nvidia,pins = "kb_row2_pr2";
                                nvidia,function = "kbc";
                                nvidia,pull = <TEGRA_PIN_PULL_UP>;
                                nvidia,tristate = <TEGRA_PIN_DISABLE>;
                                nvidia,enable-input = <TEGRA_PIN_ENABLE>;
                        };
                        kb_row3_pr3 {
                                nvidia,pins = "kb_row3_pr3";
                                nvidia,function = "kbc";
                                nvidia,pull = <TEGRA_PIN_PULL_UP>;
                                nvidia,tristate = <TEGRA_PIN_DISABLE>;
                                nvidia,enable-input = <TEGRA_PIN_ENABLE>;
                        };
                        kb_row4_pr4 {
                                nvidia,pins = "kb_row4_pr4";
                                nvidia,function = "kbc";
                                nvidia,pull = <TEGRA_PIN_PULL_UP>;
                                nvidia,tristate = <TEGRA_PIN_DISABLE>;
                                nvidia,enable-input = <TEGRA_PIN_ENABLE>;
                        };
                        kb_row5_pr5 {
                                nvidia,pins = "kb_row5_pr5";
                                nvidia,function = "kbc";
                                nvidia,pull = <TEGRA_PIN_PULL_UP>;
                                nvidia,tristate = <TEGRA_PIN_DISABLE>;
                                nvidia,enable-input = <TEGRA_PIN_ENABLE>;
                        };
                        kb_row6_pr6 {
                                nvidia,pins = "kb_row6_pr6";
                                nvidia,function = "kbc";
                                nvidia,pull = <TEGRA_PIN_PULL_UP>;
                                nvidia,tristate = <TEGRA_PIN_DISABLE>;
                                nvidia,enable-input = <TEGRA_PIN_ENABLE>;
                        };
                        kb_row7_pr7 {
                                nvidia,pins = "kb_row7_pr7";
                                nvidia,function = "kbc";
                                nvidia,pull = <TEGRA_PIN_PULL_UP>;
                                nvidia,tristate = <TEGRA_PIN_DISABLE>;
                                nvidia,enable-input = <TEGRA_PIN_ENABLE>;
                        };
                        kb_row8_ps0 {
                                nvidia,pins = "kb_row8_ps0";
                                nvidia,function = "kbc";
                                nvidia,pull = <TEGRA_PIN_PULL_UP>;
                                nvidia,tristate = <TEGRA_PIN_DISABLE>;
                                nvidia,enable-input = <TEGRA_PIN_ENABLE>;
                        };
                        kb_row9_ps1 {
                                nvidia,pins = "kb_row9_ps1";
                                nvidia,function = "kbc";
                                nvidia,pull = <TEGRA_PIN_PULL_UP>;
                                nvidia,tristate = <TEGRA_PIN_DISABLE>;
                                nvidia,enable-input = <TEGRA_PIN_ENABLE>;
                        };
                        kb_row10_ps2 {
                                nvidia,pins = "kb_row10_ps2";
                                nvidia,function = "kbc";
                                nvidia,pull = <TEGRA_PIN_PULL_UP>;
                                nvidia,tristate = <TEGRA_PIN_DISABLE>;
                                nvidia,enable-input = <TEGRA_PIN_ENABLE>;
                        };
                        kb_row11_ps3 {
                                nvidia,pins = "kb_row11_ps3";
                                nvidia,function = "kbc";
                                nvidia,pull = <TEGRA_PIN_PULL_UP>;
                                nvidia,tristate = <TEGRA_PIN_DISABLE>;
                                nvidia,enable-input = <TEGRA_PIN_ENABLE>;
                        };
                        kb_row12_ps4 {
                                nvidia,pins = "kb_row12_ps4";
                                nvidia,function = "kbc";
                                nvidia,pull = <TEGRA_PIN_PULL_UP>;
                                nvidia,tristate = <TEGRA_PIN_DISABLE>;
                                nvidia,enable-input = <TEGRA_PIN_ENABLE>;
                        };
                        kb_row13_ps5 {
                                nvidia,pins = "kb_row13_ps5";
                                nvidia,function = "kbc";
                                nvidia,pull = <TEGRA_PIN_PULL_UP>;
                                nvidia,tristate = <TEGRA_PIN_DISABLE>;
                                nvidia,enable-input = <TEGRA_PIN_ENABLE>;
                        };
                        kb_row14_ps6 {
                                nvidia,pins = "kb_row14_ps6";
                                nvidia,function = "kbc";
                                nvidia,pull = <TEGRA_PIN_PULL_UP>;
                                nvidia,tristate = <TEGRA_PIN_DISABLE>;
                                nvidia,enable-input = <TEGRA_PIN_ENABLE>;
                        };
                        kb_row15_ps7 {
                                nvidia,pins = "kb_row15_ps7";
                                nvidia,function = "kbc";
                                nvidia,pull = <TEGRA_PIN_PULL_UP>;
                                nvidia,tristate = <TEGRA_PIN_DISABLE>;
                                nvidia,enable-input = <TEGRA_PIN_ENABLE>;
                        };
                        vi_pclk_pt0 {
                                nvidia,pins = "vi_pclk_pt0";
                                nvidia,function = "rsvd1";
                                nvidia,pull = <TEGRA_PIN_PULL_UP>;
                                nvidia,tristate = <TEGRA_PIN_DISABLE>;
                                nvidia,enable-input = <TEGRA_PIN_ENABLE>;
                        };
                        vi_mclk_pt1 {
                                nvidia,pins = "vi_mclk_pt1";
                                nvidia,function = "vi";
                                nvidia,pull = <TEGRA_PIN_PULL_UP>;
                                nvidia,tristate = <TEGRA_PIN_DISABLE>;
                                nvidia,enable-input = <TEGRA_PIN_ENABLE>;
                        };
                        vi_d10_pt2 {
                                nvidia,pins = "vi_d10_pt2";
                                nvidia,function = "ddr";
                                nvidia,pull = <TEGRA_PIN_PULL_NONE>;
                                nvidia,tristate = <TEGRA_PIN_DISABLE>;
                                nvidia,enable-input = <TEGRA_PIN_ENABLE>;
                        };
                        vi_d11_pt3 {
                                nvidia,pins = "vi_d11_pt3";
                                nvidia,function = "ddr";
                                nvidia,pull = <TEGRA_PIN_PULL_UP>;
                                nvidia,tristate = <TEGRA_PIN_DISABLE>;
                                nvidia,enable-input = <TEGRA_PIN_ENABLE>;
                        };
                        vi_d0_pt4 {
                                nvidia,pins = "vi_d0_pt4";
                                nvidia,function = "ddr";
                                nvidia,pull = <TEGRA_PIN_PULL_NONE>;
                                nvidia,tristate = <TEGRA_PIN_DISABLE>;
                                nvidia,enable-input = <TEGRA_PIN_ENABLE>;
                        };
                        gen2_i2c_scl_pt5 {
                                nvidia,pins = "gen2_i2c_scl_pt5";
                                nvidia,function = "i2c2";
                                nvidia,pull = <TEGRA_PIN_PULL_NONE>;
                                nvidia,tristate = <TEGRA_PIN_DISABLE>;
                                nvidia,enable-input = <TEGRA_PIN_ENABLE>;
                                nvidia,open-drain = <TEGRA_PIN_ENABLE>;
                        };
                        gen2_i2c_sda_pt6 {
                                nvidia,pins = "gen2_i2c_sda_pt6";
                                nvidia,function = "i2c2";
                                nvidia,pull = <TEGRA_PIN_PULL_NONE>;
                                nvidia,tristate = <TEGRA_PIN_DISABLE>;
                                nvidia,enable-input = <TEGRA_PIN_ENABLE>;
                                nvidia,open-drain = <TEGRA_PIN_ENABLE>;
                        };
                        sdmmc4_cmd_pt7 {
                                nvidia,pins = "sdmmc4_cmd_pt7";
                                nvidia,function = "sdmmc4";
                                nvidia,pull = <TEGRA_PIN_PULL_UP>;
                                nvidia,tristate = <TEGRA_PIN_DISABLE>;
                                nvidia,enable-input = <TEGRA_PIN_ENABLE>;
                        };
                        pu0 {
                                nvidia,pins = "pu0";
                                nvidia,function = "owr";
                                nvidia,pull = <TEGRA_PIN_PULL_NONE>;
                                nvidia,tristate = <TEGRA_PIN_DISABLE>;
                                nvidia,enable-input = <TEGRA_PIN_ENABLE>;
                        };
                        pu1 {
                                nvidia,pins = "pu1";
                                nvidia,function = "rsvd1";
                                nvidia,pull = <TEGRA_PIN_PULL_NONE>;
                                nvidia,tristate = <TEGRA_PIN_DISABLE>;
                                nvidia,enable-input = <TEGRA_PIN_DISABLE>;
                        };
                        pu2 {
                                nvidia,pins = "pu2";
                                nvidia,function = "rsvd1";
                                nvidia,pull = <TEGRA_PIN_PULL_NONE>;
                                nvidia,tristate = <TEGRA_PIN_DISABLE>;
                                nvidia,enable-input = <TEGRA_PIN_ENABLE>;
                        };
                        pu3 {
                                nvidia,pins = "pu3";
                                nvidia,function = "pwm0";
                                nvidia,pull = <TEGRA_PIN_PULL_NONE>;
                                nvidia,tristate = <TEGRA_PIN_DISABLE>;
                                nvidia,enable-input = <TEGRA_PIN_ENABLE>;
                        };
                        pu4 {
                                nvidia,pins = "pu4";
                                nvidia,function = "pwm1";
                                nvidia,pull = <TEGRA_PIN_PULL_NONE>;
                                nvidia,tristate = <TEGRA_PIN_DISABLE>;
                                nvidia,enable-input = <TEGRA_PIN_DISABLE>;
                        };
                        pu5 {
                                nvidia,pins = "pu5";
                                nvidia,function = "pwm2";
                                nvidia,pull = <TEGRA_PIN_PULL_NONE>;
                                nvidia,tristate = <TEGRA_PIN_DISABLE>;
                                nvidia,enable-input = <TEGRA_PIN_DISABLE>;
                        };
                        pu6 {
                                nvidia,pins = "pu6";
                                nvidia,function = "pwm3";
                                nvidia,pull = <TEGRA_PIN_PULL_NONE>;
                                nvidia,tristate = <TEGRA_PIN_DISABLE>;
                                nvidia,enable-input = <TEGRA_PIN_ENABLE>;
                        };
                        jtag_rtck_pu7 {
                                nvidia,pins = "jtag_rtck_pu7";
                                nvidia,function = "rtck";
                                nvidia,pull = <TEGRA_PIN_PULL_NONE>;
                                nvidia,tristate = <TEGRA_PIN_DISABLE>;
                                nvidia,enable-input = <TEGRA_PIN_DISABLE>;
                        };
                        pv0 {
                                nvidia,pins = "pv0";
                                nvidia,function = "rsvd1";
                                nvidia,pull = <TEGRA_PIN_PULL_UP>;
                                nvidia,tristate = <TEGRA_PIN_DISABLE>;
                                nvidia,enable-input = <TEGRA_PIN_ENABLE>;
                        };
                        pv2 {
                                nvidia,pins = "pv2";
                                nvidia,function = "owr";
                                nvidia,pull = <TEGRA_PIN_PULL_NONE>;
                                nvidia,tristate = <TEGRA_PIN_DISABLE>;
                                nvidia,enable-input = <TEGRA_PIN_DISABLE>;
                        };
                        pv3 {
                                nvidia,pins = "pv3";
                                nvidia,function = "clk_12m_out";
                                nvidia,pull = <TEGRA_PIN_PULL_NONE>;
                                nvidia,tristate = <TEGRA_PIN_DISABLE>;
                                nvidia,enable-input = <TEGRA_PIN_DISABLE>;
                        };
                        ddc_scl_pv4 {
                                nvidia,pins = "ddc_scl_pv4";
                                nvidia,function = "i2c4";
                                nvidia,pull = <TEGRA_PIN_PULL_NONE>;
                                nvidia,tristate = <TEGRA_PIN_DISABLE>;
                                nvidia,enable-input = <TEGRA_PIN_ENABLE>;
                        };
                        ddc_sda_pv5 {
                                nvidia,pins = "ddc_sda_pv5";
                                nvidia,function = "i2c4";
                                nvidia,pull = <TEGRA_PIN_PULL_NONE>;
                                nvidia,tristate = <TEGRA_PIN_DISABLE>;
                                nvidia,enable-input = <TEGRA_PIN_ENABLE>;
                        };
                        crt_hsync_pv6 {
                                nvidia,pins = "crt_hsync_pv6";
                                nvidia,function = "crt";
                                nvidia,pull = <TEGRA_PIN_PULL_NONE>;
                                nvidia,tristate = <TEGRA_PIN_DISABLE>;
                                nvidia,enable-input = <TEGRA_PIN_DISABLE>;
                        };
                        crt_vsync_pv7 {
                                nvidia,pins = "crt_vsync_pv7";
                                nvidia,function = "crt";
                                nvidia,pull = <TEGRA_PIN_PULL_NONE>;
                                nvidia,tristate = <TEGRA_PIN_DISABLE>;
                                nvidia,enable-input = <TEGRA_PIN_DISABLE>;
                        };
                        lcd_cs1_n_pw0 {
                                nvidia,pins = "lcd_cs1_n_pw0";
                                nvidia,function = "displaya";
                                nvidia,pull = <TEGRA_PIN_PULL_NONE>;
                                nvidia,tristate = <TEGRA_PIN_DISABLE>;
                                nvidia,enable-input = <TEGRA_PIN_ENABLE>;
                        };
                        lcd_m1_pw1 {
                                nvidia,pins = "lcd_m1_pw1";
                                nvidia,function = "displaya";
                                nvidia,pull = <TEGRA_PIN_PULL_NONE>;
                                nvidia,tristate = <TEGRA_PIN_DISABLE>;
                                nvidia,enable-input = <TEGRA_PIN_ENABLE>;
                        };
                        spi2_cs1_n_pw2 {
                                nvidia,pins = "spi2_cs1_n_pw2";
                                nvidia,function = "spi2";
                                nvidia,pull = <TEGRA_PIN_PULL_UP>;
                                nvidia,tristate = <TEGRA_PIN_DISABLE>;
                                nvidia,enable-input = <TEGRA_PIN_ENABLE>;
                        };
                        clk1_out_pw4 {
                                nvidia,pins = "clk1_out_pw4";
                                nvidia,function = "extperiph1";
                                nvidia,pull = <TEGRA_PIN_PULL_NONE>;
                                nvidia,tristate = <TEGRA_PIN_DISABLE>;
                                nvidia,enable-input = <TEGRA_PIN_ENABLE>;
                        };
                        clk2_out_pw5 {
                                nvidia,pins = "clk2_out_pw5";
                                nvidia,function = "extperiph2";
                                nvidia,pull = <TEGRA_PIN_PULL_NONE>;
                                nvidia,tristate = <TEGRA_PIN_DISABLE>;
                                nvidia,enable-input = <TEGRA_PIN_ENABLE>;
                        };
                        uart3_txd_pw6 {
                                nvidia,pins = "uart3_txd_pw6";
                                nvidia,function = "uartc";
                                nvidia,pull = <TEGRA_PIN_PULL_NONE>;
                                nvidia,tristate = <TEGRA_PIN_DISABLE>;
                                nvidia,enable-input = <TEGRA_PIN_DISABLE>;
                        };
                        uart3_rxd_pw7 {
                                nvidia,pins = "uart3_rxd_pw7";
                                nvidia,function = "uartc";
                                nvidia,pull = <TEGRA_PIN_PULL_NONE>;
                                nvidia,tristate = <TEGRA_PIN_DISABLE>;
                                nvidia,enable-input = <TEGRA_PIN_ENABLE>;
                        };
                        spi2_sck_px2 {
                                nvidia,pins = "spi2_sck_px2";
                                nvidia,function = "gmi";
                                nvidia,pull = <TEGRA_PIN_PULL_NONE>;
                                nvidia,tristate = <TEGRA_PIN_DISABLE>;
                                nvidia,enable-input = <TEGRA_PIN_ENABLE>;
                        };
                        spi1_mosi_px4 {
                                nvidia,pins = "spi1_mosi_px4";
                                nvidia,function = "spi1";
                                nvidia,pull = <TEGRA_PIN_PULL_NONE>;
                                nvidia,tristate = <TEGRA_PIN_DISABLE>;
                                nvidia,enable-input = <TEGRA_PIN_ENABLE>;
                        };
                        spi1_sck_px5 {
                                nvidia,pins = "spi1_sck_px5";
                                nvidia,function = "spi1";
                                nvidia,pull = <TEGRA_PIN_PULL_NONE>;
                                nvidia,tristate = <TEGRA_PIN_DISABLE>;
                                nvidia,enable-input = <TEGRA_PIN_ENABLE>;
                        };
                        spi1_cs0_n_px6 {
                                nvidia,pins = "spi1_cs0_n_px6";
                                nvidia,function = "spi1";
                                nvidia,pull = <TEGRA_PIN_PULL_NONE>;
                                nvidia,tristate = <TEGRA_PIN_DISABLE>;
                                nvidia,enable-input = <TEGRA_PIN_ENABLE>;
                        };
                        spi1_miso_px7 {
                                nvidia,pins = "spi1_miso_px7";
                                nvidia,function = "spi1";
                                nvidia,pull = <TEGRA_PIN_PULL_NONE>;
                                nvidia,tristate = <TEGRA_PIN_DISABLE>;
                                nvidia,enable-input = <TEGRA_PIN_ENABLE>;
                        };
                        ulpi_clk_py0 {
                                nvidia,pins = "ulpi_clk_py0";
                                nvidia,function = "uartd";
                                nvidia,pull = <TEGRA_PIN_PULL_NONE>;
                                nvidia,tristate = <TEGRA_PIN_DISABLE>;
                                nvidia,enable-input = <TEGRA_PIN_DISABLE>;
                        };
                        ulpi_dir_py1 {
                                nvidia,pins = "ulpi_dir_py1";
                                nvidia,function = "uartd";
                                nvidia,pull = <TEGRA_PIN_PULL_NONE>;
                                nvidia,tristate = <TEGRA_PIN_DISABLE>;
                                nvidia,enable-input = <TEGRA_PIN_ENABLE>;
                        };
                        ulpi_nxt_py2 {
                                nvidia,pins = "ulpi_nxt_py2";
                                nvidia,function = "uartd";
                                nvidia,pull = <TEGRA_PIN_PULL_NONE>;
                                nvidia,tristate = <TEGRA_PIN_DISABLE>;
                                nvidia,enable-input = <TEGRA_PIN_ENABLE>;
                        };
                        ulpi_stp_py3 {
                                nvidia,pins = "ulpi_stp_py3";
                                nvidia,function = "uartd";
                                nvidia,pull = <TEGRA_PIN_PULL_NONE>;
                                nvidia,tristate = <TEGRA_PIN_DISABLE>;
                                nvidia,enable-input = <TEGRA_PIN_DISABLE>;
                        };
                        sdmmc1_dat3_py4 {
                                nvidia,pins = "sdmmc1_dat3_py4";
                                nvidia,function = "sdmmc1";
                                nvidia,pull = <TEGRA_PIN_PULL_UP>;
                                nvidia,tristate = <TEGRA_PIN_DISABLE>;
                                nvidia,enable-input = <TEGRA_PIN_ENABLE>;
                        };
                        sdmmc1_dat2_py5 {
                                nvidia,pins = "sdmmc1_dat2_py5";
                                nvidia,function = "sdmmc1";
                                nvidia,pull = <TEGRA_PIN_PULL_UP>;
                                nvidia,tristate = <TEGRA_PIN_DISABLE>;
                                nvidia,enable-input = <TEGRA_PIN_ENABLE>;
                        };
                        sdmmc1_dat1_py6 {
                                nvidia,pins = "sdmmc1_dat1_py6";
                                nvidia,function = "sdmmc1";
                                nvidia,pull = <TEGRA_PIN_PULL_UP>;
                                nvidia,tristate = <TEGRA_PIN_DISABLE>;
                                nvidia,enable-input = <TEGRA_PIN_ENABLE>;
                        };
                        sdmmc1_dat0_py7 {
                                nvidia,pins = "sdmmc1_dat0_py7";
                                nvidia,function = "sdmmc1";
                                nvidia,pull = <TEGRA_PIN_PULL_UP>;
                                nvidia,tristate = <TEGRA_PIN_DISABLE>;
                                nvidia,enable-input = <TEGRA_PIN_ENABLE>;
                        };
                        sdmmc1_clk_pz0 {
                                nvidia,pins = "sdmmc1_clk_pz0";
                                nvidia,function = "sdmmc1";
                                nvidia,pull = <TEGRA_PIN_PULL_NONE>;
                                nvidia,tristate = <TEGRA_PIN_DISABLE>;
                                nvidia,enable-input = <TEGRA_PIN_ENABLE>;
                        };
                        sdmmc1_cmd_pz1 {
                                nvidia,pins = "sdmmc1_cmd_pz1";
                                nvidia,function = "sdmmc1";
                                nvidia,pull = <TEGRA_PIN_PULL_UP>;
                                nvidia,tristate = <TEGRA_PIN_DISABLE>;
                                nvidia,enable-input = <TEGRA_PIN_ENABLE>;
                        };
                        lcd_sdin_pz2 {
                                nvidia,pins = "lcd_sdin_pz2";
                                nvidia,function = "displaya";
                                nvidia,pull = <TEGRA_PIN_PULL_NONE>;
                                nvidia,tristate = <TEGRA_PIN_DISABLE>;
                                nvidia,enable-input = <TEGRA_PIN_ENABLE>;
                        };
                        lcd_wr_n_pz3 {
                                nvidia,pins = "lcd_wr_n_pz3";
                                nvidia,function = "displaya";
                                nvidia,pull = <TEGRA_PIN_PULL_NONE>;
                                nvidia,tristate = <TEGRA_PIN_DISABLE>;
                                nvidia,enable-input = <TEGRA_PIN_ENABLE>;
                        };
                        lcd_sck_pz4 {
                                nvidia,pins = "lcd_sck_pz4";
                                nvidia,function = "displaya";
                                nvidia,pull = <TEGRA_PIN_PULL_NONE>;
                                nvidia,tristate = <TEGRA_PIN_DISABLE>;
                                nvidia,enable-input = <TEGRA_PIN_ENABLE>;
                        };
                        sys_clk_req_pz5 {
                                nvidia,pins = "sys_clk_req_pz5";
                                nvidia,function = "sysclk";
                                nvidia,pull = <TEGRA_PIN_PULL_NONE>;
                                nvidia,tristate = <TEGRA_PIN_DISABLE>;
                                nvidia,enable-input = <TEGRA_PIN_DISABLE>;
                        };
                        pwr_i2c_scl_pz6 {
                                nvidia,pins = "pwr_i2c_scl_pz6";
                                nvidia,function = "i2cpwr";
                                nvidia,pull = <TEGRA_PIN_PULL_NONE>;
                                nvidia,tristate = <TEGRA_PIN_DISABLE>;
                                nvidia,enable-input = <TEGRA_PIN_ENABLE>;
                                nvidia,open-drain = <TEGRA_PIN_ENABLE>;
                        };
                        pwr_i2c_sda_pz7 {
                                nvidia,pins = "pwr_i2c_sda_pz7";
                                nvidia,function = "i2cpwr";
                                nvidia,pull = <TEGRA_PIN_PULL_NONE>;
                                nvidia,tristate = <TEGRA_PIN_DISABLE>;
                                nvidia,enable-input = <TEGRA_PIN_ENABLE>;
                                nvidia,open-drain = <TEGRA_PIN_ENABLE>;
                        };
                        sdmmc4_dat0_paa0 {
                                nvidia,pins = "sdmmc4_dat0_paa0";
                                nvidia,function = "sdmmc4";
                                nvidia,pull = <TEGRA_PIN_PULL_UP>;
                                nvidia,tristate = <TEGRA_PIN_DISABLE>;
                                nvidia,enable-input = <TEGRA_PIN_ENABLE>;
                        };
                        sdmmc4_dat1_paa1 {
                                nvidia,pins = "sdmmc4_dat1_paa1";
                                nvidia,function = "sdmmc4";
                                nvidia,pull = <TEGRA_PIN_PULL_UP>;
                                nvidia,tristate = <TEGRA_PIN_DISABLE>;
                                nvidia,enable-input = <TEGRA_PIN_ENABLE>;
                        };
                        sdmmc4_dat2_paa2 {
                                nvidia,pins = "sdmmc4_dat2_paa2";
                                nvidia,function = "sdmmc4";
                                nvidia,pull = <TEGRA_PIN_PULL_UP>;
                                nvidia,tristate = <TEGRA_PIN_DISABLE>;
                                nvidia,enable-input = <TEGRA_PIN_ENABLE>;
                        };
                        sdmmc4_dat3_paa3 {
                                nvidia,pins = "sdmmc4_dat3_paa3";
                                nvidia,function = "sdmmc4";
                                nvidia,pull = <TEGRA_PIN_PULL_UP>;
                                nvidia,tristate = <TEGRA_PIN_DISABLE>;
                                nvidia,enable-input = <TEGRA_PIN_ENABLE>;
                        };
                        sdmmc4_dat4_paa4 {
                                nvidia,pins = "sdmmc4_dat4_paa4";
                                nvidia,function = "sdmmc4";
                                nvidia,pull = <TEGRA_PIN_PULL_UP>;
                                nvidia,tristate = <TEGRA_PIN_DISABLE>;
                                nvidia,enable-input = <TEGRA_PIN_ENABLE>;
			};
                        sdmmc4_dat5_paa5 {
                                nvidia,pins = "sdmmc4_dat5_paa5";
                                nvidia,function = "sdmmc4";
                                nvidia,pull = <TEGRA_PIN_PULL_UP>;
                                nvidia,tristate = <TEGRA_PIN_DISABLE>;
                                nvidia,enable-input = <TEGRA_PIN_ENABLE>;
                        };
                        sdmmc4_dat6_paa6 {
                                nvidia,pins = "sdmmc4_dat6_paa6";
                                nvidia,function = "sdmmc4";
                                nvidia,pull = <TEGRA_PIN_PULL_UP>;
                                nvidia,tristate = <TEGRA_PIN_DISABLE>;
                                nvidia,enable-input = <TEGRA_PIN_ENABLE>;
                        };
                        sdmmc4_dat7_paa7 {
                                nvidia,pins = "sdmmc4_dat7_paa7";
                                nvidia,function = "sdmmc4";
                                nvidia,pull = <TEGRA_PIN_PULL_UP>;
                                nvidia,tristate = <TEGRA_PIN_DISABLE>;
                                nvidia,enable-input = <TEGRA_PIN_ENABLE>;
                        };
                        pbb0 {
                                nvidia,pins = "pbb0";
                                nvidia,function = "i2s4";
                                nvidia,pull = <TEGRA_PIN_PULL_NONE>;
                                nvidia,tristate = <TEGRA_PIN_DISABLE>;
                                nvidia,enable-input = <TEGRA_PIN_ENABLE>;
                        };
                        cam_i2c_scl_pbb1 {
                                nvidia,pins = "cam_i2c_scl_pbb1";
                                nvidia,function = "i2c3";
                                nvidia,pull = <TEGRA_PIN_PULL_NONE>;
                                nvidia,tristate = <TEGRA_PIN_DISABLE>;
                                nvidia,enable-input = <TEGRA_PIN_ENABLE>;
                                nvidia,open-drain = <TEGRA_PIN_ENABLE>;
                        };
                        cam_i2c_sda_pbb2 {
                                nvidia,pins = "cam_i2c_sda_pbb2";
                                nvidia,function = "i2c3";
                                nvidia,pull = <TEGRA_PIN_PULL_NONE>;
                                nvidia,tristate = <TEGRA_PIN_DISABLE>;
                                nvidia,enable-input = <TEGRA_PIN_ENABLE>;
                                nvidia,open-drain = <TEGRA_PIN_ENABLE>;
                        };
                        pbb3 {
                                nvidia,pins = "pbb3";
                                nvidia,function = "vgp3";
                                nvidia,pull = <TEGRA_PIN_PULL_NONE>;
                                nvidia,tristate = <TEGRA_PIN_DISABLE>;
                                nvidia,enable-input = <TEGRA_PIN_ENABLE>;
                        };
                        pbb4 {
                                nvidia,pins = "pbb4";
                                nvidia,function = "vgp4";
                                nvidia,pull = <TEGRA_PIN_PULL_NONE>;
                                nvidia,tristate = <TEGRA_PIN_DISABLE>;
                                nvidia,enable-input = <TEGRA_PIN_ENABLE>;
                        };
                        pbb5 {
                                nvidia,pins = "pbb5";
                                nvidia,function = "vgp5";
                                nvidia,pull = <TEGRA_PIN_PULL_NONE>;
                                nvidia,tristate = <TEGRA_PIN_DISABLE>;
                                nvidia,enable-input = <TEGRA_PIN_ENABLE>;
                        };
                        pbb6 {
                                nvidia,pins = "pbb6";
                                nvidia,function = "vgp6";
                                nvidia,pull = <TEGRA_PIN_PULL_NONE>;
                                nvidia,tristate = <TEGRA_PIN_DISABLE>;
                                nvidia,enable-input = <TEGRA_PIN_ENABLE>;
                        };
                        pbb7 {
                                nvidia,pins = "pbb7";
                                nvidia,function = "i2s4";
                                nvidia,pull = <TEGRA_PIN_PULL_NONE>;
                                nvidia,tristate = <TEGRA_PIN_DISABLE>;
                                nvidia,enable-input = <TEGRA_PIN_ENABLE>;
                        };
                        cam_mclk_pcc0 {
                                nvidia,pins = "cam_mclk_pcc0";
                                nvidia,function = "vi_alt3";
                                nvidia,pull = <TEGRA_PIN_PULL_UP>;
                                nvidia,tristate = <TEGRA_PIN_DISABLE>;
                                nvidia,enable-input = <TEGRA_PIN_ENABLE>;
                        };
                        pcc1 {
                                nvidia,pins = "pcc1";
                                nvidia,function = "i2s4";
                                nvidia,pull = <TEGRA_PIN_PULL_NONE>;
                                nvidia,tristate = <TEGRA_PIN_DISABLE>;
                                nvidia,enable-input = <TEGRA_PIN_ENABLE>;
                        };
                        pcc2 {
                                nvidia,pins = "pcc2";
                                nvidia,function = "i2s4";
                                nvidia,pull = <TEGRA_PIN_PULL_NONE>;
                                nvidia,tristate = <TEGRA_PIN_DISABLE>;
                                nvidia,enable-input = <TEGRA_PIN_ENABLE>;
                        };
                        sdmmc4_rst_n_pcc3 {
                                nvidia,pins = "sdmmc4_rst_n_pcc3";
                                nvidia,function = "sdmmc4";
                                nvidia,pull = <TEGRA_PIN_PULL_DOWN>;
                                nvidia,tristate = <TEGRA_PIN_DISABLE>;
                                nvidia,enable-input = <TEGRA_PIN_ENABLE>;
                        };
                        sdmmc4_clk_pcc4 {
                                nvidia,pins = "sdmmc4_clk_pcc4";
                                nvidia,function = "sdmmc4";
                                nvidia,pull = <TEGRA_PIN_PULL_NONE>;
                                nvidia,tristate = <TEGRA_PIN_DISABLE>;
                                nvidia,enable-input = <TEGRA_PIN_ENABLE>;
                        };
                        clk2_req_pcc5 {
                                nvidia,pins = "clk2_req_pcc5";
                                nvidia,function = "dap";
                                nvidia,pull = <TEGRA_PIN_PULL_NONE>;
                                nvidia,tristate = <TEGRA_PIN_DISABLE>;
                                nvidia,enable-input = <TEGRA_PIN_ENABLE>;
                        };
                        pex_l2_rst_n_pcc6 {
                                nvidia,pins = "pex_l2_rst_n_pcc6";
                                nvidia,function = "pcie";
                                nvidia,pull = <TEGRA_PIN_PULL_NONE>;
                                nvidia,tristate = <TEGRA_PIN_DISABLE>;
                                nvidia,enable-input = <TEGRA_PIN_DISABLE>;
                        };
                        pex_l2_clkreq_n_pcc7 {
                                nvidia,pins = "pex_l2_clkreq_n_pcc7";
                                nvidia,function = "pcie";
                                nvidia,pull = <TEGRA_PIN_PULL_NONE>;
                                nvidia,tristate = <TEGRA_PIN_DISABLE>;
                                nvidia,enable-input = <TEGRA_PIN_ENABLE>;
                        };
                        pex_l0_prsnt_n_pdd0 {
                                nvidia,pins = "pex_l0_prsnt_n_pdd0";
                                nvidia,function = "pcie";
                                nvidia,pull = <TEGRA_PIN_PULL_NONE>;
                                nvidia,tristate = <TEGRA_PIN_DISABLE>;
                                nvidia,enable-input = <TEGRA_PIN_ENABLE>;
                        };
                        pex_l0_rst_n_pdd1 {
                                nvidia,pins = "pex_l0_rst_n_pdd1";
                                nvidia,function = "pcie";
                                nvidia,pull = <TEGRA_PIN_PULL_NONE>;
                                nvidia,tristate = <TEGRA_PIN_DISABLE>;
                                nvidia,enable-input = <TEGRA_PIN_DISABLE>;
                        };
                        pex_l0_clkreq_n_pdd2 {
                                nvidia,pins = "pex_l0_clkreq_n_pdd2";
                                nvidia,function = "pcie";
                                nvidia,pull = <TEGRA_PIN_PULL_NONE>;
                                nvidia,tristate = <TEGRA_PIN_DISABLE>;
                                nvidia,enable-input = <TEGRA_PIN_ENABLE>;
                        };
                        pex_wake_n_pdd3 {
                                nvidia,pins = "pex_wake_n_pdd3";
                                nvidia,function = "pcie";
                                nvidia,pull = <TEGRA_PIN_PULL_NONE>;
                                nvidia,tristate = <TEGRA_PIN_DISABLE>;
                                nvidia,enable-input = <TEGRA_PIN_ENABLE>;
                        };
                        pex_l1_prsnt_n_pdd4 {
                                nvidia,pins = "pex_l1_prsnt_n_pdd4";
                                nvidia,function = "pcie";
                                nvidia,pull = <TEGRA_PIN_PULL_UP>;
                                nvidia,tristate = <TEGRA_PIN_DISABLE>;
                                nvidia,enable-input = <TEGRA_PIN_ENABLE>;
                        };
                        pex_l1_rst_n_pdd5 {
                                nvidia,pins = "pex_l1_rst_n_pdd5";
                                nvidia,function = "pcie";
                                nvidia,pull = <TEGRA_PIN_PULL_NONE>;
                                nvidia,tristate = <TEGRA_PIN_DISABLE>;
                                nvidia,enable-input = <TEGRA_PIN_DISABLE>;
                        };
                        pex_l1_clkreq_n_pdd6 {
                                nvidia,pins = "pex_l1_clkreq_n_pdd6";
                                nvidia,function = "pcie";
                                nvidia,pull = <TEGRA_PIN_PULL_UP>;
                                nvidia,tristate = <TEGRA_PIN_DISABLE>;
                                nvidia,enable-input = <TEGRA_PIN_ENABLE>;
                        };
                        pex_l2_prsnt_n_pdd7 {
                                nvidia,pins = "pex_l2_prsnt_n_pdd7";
                                nvidia,function = "pcie";
                                nvidia,pull = <TEGRA_PIN_PULL_NONE>;
                                nvidia,tristate = <TEGRA_PIN_DISABLE>;
                                nvidia,enable-input = <TEGRA_PIN_ENABLE>;
                        };
                        clk3_out_pee0 {
                                nvidia,pins = "clk3_out_pee0";
                                nvidia,function = "extperiph3";
                                nvidia,pull = <TEGRA_PIN_PULL_NONE>;
                                nvidia,tristate = <TEGRA_PIN_DISABLE>;
                                nvidia,enable-input = <TEGRA_PIN_DISABLE>;
                        };
                        clk3_req_pee1 {
                                nvidia,pins = "clk3_req_pee1";
                                nvidia,function = "dev3";
                                nvidia,pull = <TEGRA_PIN_PULL_NONE>;
                                nvidia,tristate = <TEGRA_PIN_DISABLE>;
                                nvidia,enable-input = <TEGRA_PIN_ENABLE>;
                        };
                        clk1_req_pee2 {
                                nvidia,pins = "clk1_req_pee2";
                                nvidia,function = "dap";
                                nvidia,pull = <TEGRA_PIN_PULL_NONE>;
                                nvidia,tristate = <TEGRA_PIN_DISABLE>;
                                nvidia,enable-input = <TEGRA_PIN_ENABLE>;
                        };
                        hdmi_cec_pee3 {
                                nvidia,pins = "hdmi_cec_pee3";
                                nvidia,function = "cec";
                                nvidia,pull = <TEGRA_PIN_PULL_NONE>;
                                nvidia,tristate = <TEGRA_PIN_DISABLE>;
                                nvidia,enable-input = <TEGRA_PIN_ENABLE>;
                                nvidia,open-drain = <TEGRA_PIN_DISABLE>;
                        };
                        owr {
                                nvidia,pins = "owr";
                                nvidia,function = "owr";
                                nvidia,pull = <TEGRA_PIN_PULL_NONE>;
                                nvidia,tristate = <TEGRA_PIN_DISABLE>;
                                nvidia,enable-input = <TEGRA_PIN_ENABLE>;
                        };
		};

		sdmmc4_default:pinmux {
			sdmmc4_clk {
				nvidia,pins = "sdmmc4_clk_pcc4";
			};
			sdmmc4_cmd {
				nvidia,pins = "sdmmc4_cmd_pt7";
			};
			sdmmc4_dat0 {
				nvidia,pins = "sdmmc4_dat0_paa0",
					      "sdmmc4_dat1_paa1",
					      "sdmmc4_dat2_paa2",
					      "sdmmc4_dat3_paa3",
					      "sdmmc4_dat4_paa4",
					      "sdmmc4_dat5_paa5",
					      "sdmmc4_dat6_paa6",
					      "sdmmc4_dat7_paa7",
					      "sdmmc4_rst_n_pcc3";
			};
			drive_groups {
				nvidia,pins = "drive_gma",
					      "drive_gmb",
					      "drive_gmc",
					      "drive_gmd";
				nvidia,pull-down-strength = <31>;
				nvidia,pull-up-strength = <31>;
				nvidia,slew-rate-rising = <TEGRA_PIN_SLEW_RATE_SLOWEST>;
				nvidia,slew-rate-falling = <TEGRA_PIN_SLEW_RATE_SLOWEST>;
			};
		};
	};

	serial@70006200 {
		status = "okay";
		compatible = "nvidia,tegra30-hsuart";

		bluetooth {
			compatible = "brcm,bcm43438-bt";
			shutdown-gpios = <&gpio TEGRA_GPIO(U, 0) GPIO_ACTIVE_HIGH>;
			device-wakeup-gpios = <&gpio TEGRA_GPIO(U, 1) GPIO_ACTIVE_HIGH>;
			host-wakeup-gpios = <&gpio TEGRA_GPIO(U, 6) GPIO_ACTIVE_LOW>;
		};
	};

	serial@70006300 {
		status = "okay";
	};

	hdmi_ddc:i2c@7000c700 {
		status = "okay";
		clock-frequency = <100000>;
	};

	i2c@7000d000 {
		status = "okay";
		multi-master;
		clock-frequency = <400000>;
		cpu_temp: nct1008@4c {
			compatible = "onnn,nct1008";
			reg = <0x4c>;
			vcc-supply = <&sys_3v3_reg>;
			#thermal-sensor-cells = <1>;
//			interrupt-parent = <&gpio>;
//			interrupts = <TEGRA_GPIO(CC, 2) IRQ_TYPE_LEVEL_LOW>;
			update-interval = <4000>;
/*			local-low = <5000>;
			local-high = <80000>;
			local-critical = <90000>;
			remote-low = <10>;
			remote-high = <90000>;
			remote-critical = <100000>;
			remote-offset = <(-1000)>;
*/		};

		pmic: tps65911@2d {
			compatible = "ti,tps65911";
			reg = <0x2d>;

			interrupts = <GIC_SPI 86 IRQ_TYPE_LEVEL_HIGH>;
			#interrupt-cells = <2>;
			interrupt-controller;

			ti,system-power-controller;

			#gpio-cells = <2>;
			gpio-controller;

			vcc1-supply = <&vdd_ac_bat_reg>;
			vcc2-supply = <&vdd_ac_bat_reg>;
			vcc3-supply = <&vio_reg>;
			vcc4-supply = <&vdd_5v0_reg>;
			vcc5-supply = <&vdd_ac_bat_reg>;
			vcc6-supply = <&vdd2_reg>;
			vcc7-supply = <&vdd_ac_bat_reg>;
			vccio-supply = <&vdd_ac_bat_reg>;

			regulators {
				vdd1_reg: vdd1 {
					regulator-name = "vddio_ddr_1v2";
					regulator-min-microvolt = <1300000>;
					regulator-max-microvolt = <1300000>;
					regulator-always-on;
				};

				vdd2_reg: vdd2 {
					regulator-name = "vdd_1v5_gen";
					regulator-min-microvolt = <1500000>;
					regulator-max-microvolt = <1500000>;
					regulator-always-on;
				};

				vddctrl_reg: vddctrl {
					regulator-name = "vdd_cpu,vdd_sys";
					regulator-min-microvolt = <950000>;
					regulator-max-microvolt = <1350000>;
					regulator-always-on;
				};

				vio_reg: vio {
					regulator-name = "vdd_1v8_gen";
					regulator-min-microvolt = <1800000>;
					regulator-max-microvolt = <1800000>;
					regulator-always-on;
				};

				ldo1_reg: ldo1 {
					regulator-name = "vdd_pexa,vdd_pexb";
					regulator-min-microvolt = <1050000>;
					regulator-max-microvolt = <1050000>;
					regulator-always-on;
				};

				ldo2_reg: ldo2 {
					regulator-name = "vdd_sata,avdd_plle";
					regulator-min-microvolt = <1050000>;
					regulator-max-microvolt = <1050000>;
					regulator-always-on;
				};

				/* LDO3 is not connected to anything */

				ldo4_reg: ldo4 {
					regulator-name = "vdd_rtc";
					regulator-min-microvolt = <1200000>;
					regulator-max-microvolt = <1200000>;
					regulator-always-on;
				};

				ldo5_reg: ldo5 {
					regulator-name = "vddio_sdmmc,avdd_vdac";
					regulator-min-microvolt = <1800000>;
					regulator-max-microvolt = <3300000>;
					regulator-always-on;
				};

				ldo6_reg: ldo6 {
					regulator-name = "avdd_dsi_csi,pwrdet_mipi";
					regulator-min-microvolt = <1200000>;
					regulator-max-microvolt = <1200000>;
					regulator-always-on;
				};

				ldo7_reg: ldo7 {
					regulator-name = "vdd_pllm,x,u,a_p_c_s";
					regulator-min-microvolt = <1200000>;
					regulator-max-microvolt = <1200000>;
					regulator-always-on;
				};

				ldo8_reg: ldo8 {
					regulator-name = "vdd_ddr_hs";
					regulator-min-microvolt = <1000000>;
					regulator-max-microvolt = <1000000>;
					regulator-always-on;
				};
			};
		};

		core_vdd_reg: tps62361@60 {
			compatible = "ti,tps62361";
			reg = <0x60>;

			regulator-name = "tps62361-vout";
			regulator-min-microvolt = <500000>;
			regulator-max-microvolt = <1770000>;
			vin-supply = <&vdd1_reg>;
			regulator-boot-on;
			regulator-always-on;
			ti,vsel0-state-high;
			ti,vsel1-state-high;
		};
	};

	pmc@7000e400 {
		nvidia,suspend-mode = <0>;
		nvidia,lp0-vec = <0xbddf9000 8192>;
		status = "okay";
		nvidia,invert-interrupt;
		nvidia,suspend-mode = <1>;
		nvidia,cpu-pwr-good-time = <2000>;
		nvidia,cpu-pwr-off-time = <200>;
		nvidia,core-pwr-good-time = <3845 3845>;
		nvidia,core-pwr-off-time = <0>;
		nvidia,core-power-req-active-high;
		nvidia,sys-clock-req-active-high;
	};

	 memory-controller@7000f000 {
		emc-timings-0 {
			nvidia,ram-code = <0>;
			timing-80000000 {
				clock-frequency = <80000000>;

				nvidia,emc-zcal-cnt-long = <0x00000040>;
				nvidia,emc-auto-cal-interval = <0x001fffff>;
				nvidia,emc-mode-reset = <0x80000d71>;
				nvidia,emc-mode-1 = <0x80100002>;
				nvidia,emc-mode-2 = <0x80200018>;

				nvidia,emem-configuration = <
					0x00000025 /* EMC_RC */
					0x000000ce /* EMC_RFC */
					0x0000001a /* EMC_RAS */
					0x00000009 /* EMC_RP */
					0x00000005 /* EMC_R2W */
					0x0000000d /* EMC_W2R */
					0x00000004 /* EMC_R2P */
					0x00000013 /* EMC_W2P */
					0x00000009 /* EMC_RD_RCD */
					0x00000009 /* EMC_WR_RCD */
					0x00000004 /* EMC_RRD */
					0x00000001 /* EMC_REXT */
					0x00000000 /* EMC_WEXT */
					0x00000007 /* EMC_WDV */
					0x0000000a /* EMC_QUSE */
					0x00000009 /* EMC_QRST */
					0x0000000b /* EMC_QSAFE */
					0x00000011 /* EMC_RDV */
					0x00001820 /* EMC_REFRESH */
					0x00000000 /* EMC_BURST_REFRESH_NUM */
					0x00000608 /* EMC_PRE_REFRESH_REQ_CNT */
					0x00000003 /* EMC_PDEX2WR */
					0x00000012 /* EMC_PDEX2RD */
					0x00000001 /* EMC_PCHG2PDEN */
					0x00000000 /* EMC_ACT2PDEN */
					0x0000000f /* EMC_AR2PDEN */
					0x00000018 /* EMC_RW2PDEN */
					0x000000d8 /* EMC_TXSR */
					0x00000200 /* EMC_TXSRDLL */
					0x00000005 /* EMC_TCKE */
					0x00000020 /* EMC_TFAW */
					0x00000000 /* EMC_TRPAB */
					0x00000007 /* EMC_TCLKSTABLE */
					0x00000008 /* EMC_TCLKSTOP */
					0x00001860 /* EMC_TREFBW */
					0x0000000b /* EMC_QUSE_EXTRA */
					0x00000006 /* EMC_FBIO_CFG6 */
					0x00000000 /* EMC_ODT_WRITE */
					0x00000000 /* EMC_ODT_READ */
					0x00005088 /* EMC_FBIO_CFG5 */
					0xf0070191 /* EMC_CFG_DIG_DLL */
					0x00008000 /* EMC_CFG_DIG_DLL_PERIOD */
					0x0000800a /* EMC_DLL_XFORM_DQS0 */
					0x0000000a /* EMC_DLL_XFORM_DQS1 */
					0x0000000a /* EMC_DLL_XFORM_DQS2 */
					0x0000000a /* EMC_DLL_XFORM_DQS3 */
					0x0000000a /* EMC_DLL_XFORM_DQS4 */
					0x0000000a /* EMC_DLL_XFORM_DQS5 */
					0x0000000a /* EMC_DLL_XFORM_DQS6 */
					0x0000000a /* EMC_DLL_XFORM_DQS7 */
					0x00018000 /* EMC_DLL_XFORM_QUSE0 */
					0x00018000 /* EMC_DLL_XFORM_QUSE1 */
					0x00018000 /* EMC_DLL_XFORM_QUSE2 */
					0x00018000 /* EMC_DLL_XFORM_QUSE3 */
					0x00018000 /* EMC_DLL_XFORM_QUSE4 */
					0x00018000 /* EMC_DLL_XFORM_QUSE5 */
					0x00018000 /* EMC_DLL_XFORM_QUSE6 */
					0x00018000 /* EMC_DLL_XFORM_QUSE7 */
					0x00000000 /* EMC_DLI_TRIM_TXDQS0 */
					0x00000000 /* EMC_DLI_TRIM_TXDQS1 */
					0x00000000 /* EMC_DLI_TRIM_TXDQS2 */
					0x00000000 /* EMC_DLI_TRIM_TXDQS3 */
					0x00000000 /* EMC_DLI_TRIM_TXDQS4 */
					0x00000000 /* EMC_DLI_TRIM_TXDQS5 */
					0x00000000 /* EMC_DLI_TRIM_TXDQS6 */
					0x00000000 /* EMC_DLI_TRIM_TXDQS7 */
					0x0000000a /* EMC_DLL_XFORM_DQ0 */
					0x0000000a /* EMC_DLL_XFORM_DQ1 */
					0x0000000a /* EMC_DLL_XFORM_DQ2 */
					0x0000000a /* EMC_DLL_XFORM_DQ3 */
					0x000002a0 /* EMC_XM2CMDPADCTRL */
					0x0600013d /* EMC_XM2DQSPADCTRL2 */
					0x22220000 /* EMC_XM2DQPADCTRL2 */
					0x77fff884 /* EMC_XM2CLKPADCTRL */
					0x01f1f501 /* EMC_XM2COMPPADCTRL */
					0x07077404 /* EMC_XM2VTTGENPADCTRL */
					0x54000000 /* EMC_XM2VTTGENPADCTRL2 */
					0x080001e8 /* EMC_XM2QUSEPADCTRL */
					0x08000021 /* EMC_XM2DQSPADCTRL3 */
					0x00000802 /* EMC_CTT_TERM_CTRL */
					0x00020000 /* EMC_ZCAL_INTERVAL */
					0x00000100 /* EMC_ZCAL_WAIT_CNT */
					0x00f0000c /* EMC_MRS_WAIT_CNT */
					0xa0f10000 /* EMC_AUTO_CAL_CONFIG */
					0x00000000 /* EMC_CTT */
					0x00000000 /* EMC_CTT_DURATION */
					0x8000308c /* EMC_DYN_SELF_REF_CONTROL */
					0x00000018 /* MC_EMEM_ARB_CFG */
					0xc0000090 /* MC_EMEM_ARB_OUTSTANDING_REQ */
					0x00000004 /* MC_EMEM_ARB_TIMING_RCD */
					0x00000005 /* MC_EMEM_ARB_TIMING_RP */
					0x00000013 /* MC_EMEM_ARB_TIMING_RC */
					0x0000000c /* MC_EMEM_ARB_TIMING_RAS */
					0x0000000f /* MC_EMEM_ARB_TIMING_FAW */
					0x00000002 /* MC_EMEM_ARB_TIMING_RRD */
					0x00000003 /* MC_EMEM_ARB_TIMING_RAP2PRE */
					0x0000000c /* MC_EMEM_ARB_TIMING_WAP2PRE */
					0x00000002 /* MC_EMEM_ARB_TIMING_R2R */
					0x00000002 /* MC_EMEM_ARB_TIMING_W2W */
					0x00000004 /* MC_EMEM_ARB_TIMING_R2W */
					0x00000008 /* MC_EMEM_ARB_TIMING_W2R */
					0x08040202 /* MC_EMEM_ARB_DA_TURNS */
					0x00160d13 /* MC_EMEM_ARB_DA_COVERS */
					0x712c2414 /* MC_EMEM_ARB_MISC0 */
					0x001f0000 /* MC_EMEM_ARB_RING1_THROTTLE */
					0xe8000000 /* EMC_FBIO_SPARE */
					0xff00ff49 /* EMC_CFG_RSV */
				>;
			};
		};
	};

	ahub@70080000 {
		status = "okay";
		i2s@70080400 {
			status = "okay";
		};
	};

	sdhci@78000400 {
		status = "okay";
		non-removable;
		vmmc-supply = <&sdmmc_3v3_reg>;
/*		power-gpios = <&gpio TEGRA_GPIO(D, 4) GPIO_ACTIVE_HIGH>; */
		bus-width = <4>;
		mmc-pwrseq = <&sdhci3_pwrseq>;

		brcmf: wifi@1 {
			compatible = "brcm,bcm4329-fmac";
		};
	};

	sdhci@78000600 {
		compatible = "nvidia,tegra30-sdhci";
		status = "okay";
		non-removable;
		nvidia,only-1-8-v;
		keep-power-in-suspend;
		cap-mmc-highspeed;
//		mmc-ddr-1_8v;
		mmc-hs200-1_8v;
		max-frequency = <25500000>;
		bus-width = <8>;
		pinctrl-0 = <&sdmmc4_default>;
	};

	usb@7d000000 {
		compatible = "nvidia,tegra30-ehci", "nvidia,tegra30-udc";
		status = "okay";
	};

	usb-phy@7d000000 {
		status = "okay";
		dr_mode = "peripheral";
	};

	usb@7d004000 {
		status = "okay";
		#address-cells = <1>;
		#size-cells = <0>;

		smsc@2 { /* SMSC 10/100T Ethernet Controller */
			compatible = "usb424,9e00";
			reg = <2>;
			local-mac-address = [00 11 22 33 44 55];
		};
	};

	usb-phy@7d004000 {
		vbus-supply = <&vdd_smsc>;
		nvidia,hssync-start-delay = <0>;
		nvidia,xcvr-setup = <15>;
		nvidia,xcvr-hsslew = <8>;
		nvidia,hsdiscon-level = <1>;
		status = "okay";
	};

	usb@7d008000 {
		status = "okay";
	};

	usb-phy@7d008000 {
		vbus-supply = <&usb3_vbus_reg>;
		status = "okay";
		nvidia,xcvr-setup = <8>;
		nvidia,xcvr-hsslew = <8>;
		nvidia,hsdiscon-level = <1>;
	};

	clocks {
		compatible = "simple-bus";
		#address-cells = <1>;
		#size-cells = <0>;

		clk32k_in: clock@0 {
			compatible = "fixed-clock";
			reg = <0>;
			#clock-cells = <0>;
			clock-frequency = <32768>;
		};
	};

	vdd_ac_bat_reg: vdd_ac_bat_reg {
		compatible = "regulator-fixed";
		regulator-name = "vdd_ac_bat";
		regulator-min-microvolt = <5000000>;
		regulator-max-microvolt = <5000000>;
		regulator-always-on;
	};

	cam_1v8_reg: cam_1v8_reg {
		compatible = "regulator-fixed";
		regulator-name = "cam_1v8";
		regulator-min-microvolt = <1800000>;
		regulator-max-microvolt = <1800000>;
		enable-active-high;
		gpio = <&gpio TEGRA_GPIO(BB, 4) GPIO_ACTIVE_HIGH>;
		vin-supply = <&vio_reg>;
	};

	cp_5v_reg: cp_5v_reg {
		compatible = "regulator-fixed";
		regulator-name = "cp_5v";
		regulator-min-microvolt = <5000000>;
		regulator-max-microvolt = <5000000>;
		enable-active-high;
		gpio = <&pmic 0 GPIO_ACTIVE_HIGH>;
		vin-supply = <&vdd_ac_bat_reg>;
		system-power-controller;
		regulator-always-on;
		regulator-boot-on;
	};

	emmc_3v3_reg: emmc_3v3_reg {
		compatible = "regulator-fixed";
		regulator-name = "emmc_3v3";
		regulator-min-microvolt = <3300000>;
		regulator-max-microvolt = <3300000>;
		enable-active-high;
		gpio = <&gpio TEGRA_GPIO(D, 1) GPIO_ACTIVE_HIGH>;
		vin-supply = <&sys_3v3_reg>;
		regulator-always-on;
		regulator-boot-on;
	};

	sdmmc_3v3_reg: sdmmc_3v3_reg {
		compatible = "regulator-fixed";
		regulator-name = "sdmmc_3v3";
		regulator-min-microvolt = <3300000>;
		regulator-max-microvolt = <3300000>;
		enable-active-high;
		gpio = <&gpio TEGRA_GPIO(D, 4) GPIO_ACTIVE_HIGH>;
		vin-supply = <&sys_3v3_reg>;
	};

	modem_3v3_reg: modem_3v3_reg {
		compatible = "regulator-fixed";
		regulator-name = "modem_3v3";
		regulator-min-microvolt = <3300000>;
		regulator-max-microvolt = <3300000>;
		enable-active-high;
		gpio = <&gpio TEGRA_GPIO(D, 6) GPIO_ACTIVE_HIGH>;
	};

	pex_hvdd_3v3_reg: pex_hvdd_3v3_reg {
		compatible = "regulator-fixed";
		regulator-name = "pex_hvdd_3v3";
		regulator-min-microvolt = <3300000>;
		regulator-max-microvolt = <3300000>;
		enable-active-high;
		gpio = <&gpio TEGRA_GPIO(L, 7) GPIO_ACTIVE_HIGH>;
		vin-supply = <&sys_3v3_reg>;
	};

	vdd_cam1_ldo_reg: vdd_cam1_ldo_reg {
		compatible = "regulator-fixed";
		regulator-name = "vdd_cam1_ldo";
		regulator-min-microvolt = <2800000>;
		regulator-max-microvolt = <2800000>;
		enable-active-high;
		gpio = <&gpio TEGRA_GPIO(R, 6) GPIO_ACTIVE_HIGH>;
		vin-supply = <&sys_3v3_reg>;
		regulator-always-on;
		regulator-boot-on;
	};

	vdd_cam2_ldo_reg: vdd_cam2_ldo_reg {
		compatible = "regulator-fixed";
		regulator-name = "vdd_cam2_ldo";
		regulator-min-microvolt = <2800000>;
		regulator-max-microvolt = <2800000>;
		enable-active-high;
		gpio = <&gpio TEGRA_GPIO(R, 7) GPIO_ACTIVE_HIGH>;
		vin-supply = <&sys_3v3_reg>;
		regulator-always-on;
		regulator-boot-on;
	};

	vdd_cam3_ldo_reg: vdd_cam3_ldo_reg {
		compatible = "regulator-fixed";
		regulator-name = "vdd_cam3_ldo";
		regulator-min-microvolt = <3300000>;
		regulator-max-microvolt = <3300000>;
		enable-active-high;
		gpio = <&gpio TEGRA_GPIO(S, 0) GPIO_ACTIVE_HIGH>;
		vin-supply = <&sys_3v3_reg>;
	};

	vdd_com_reg: vdd_com_reg {
		compatible = "regulator-fixed";
		regulator-name = "vdd_com";
		regulator-min-microvolt = <3300000>;
		regulator-max-microvolt = <3300000>;
		enable-active-high;
		gpio = <&gpio TEGRA_GPIO(D, 0) GPIO_ACTIVE_HIGH>;
		vin-supply = <&sys_3v3_reg>;
		regulator-always-on;
		regulator-boot-on;
	};

	vdd_fuse_3v3_reg: vdd_fuse_3v3_reg {
		compatible = "regulator-fixed";
		regulator-name = "vdd_fuse_3v3";
		regulator-min-microvolt = <3300000>;
		regulator-max-microvolt = <3300000>;
		enable-active-high;
		gpio = <&gpio TEGRA_GPIO(L, 6) GPIO_ACTIVE_HIGH>;
		vin-supply = <&sys_3v3_reg>;
		regulator-always-on;
	};

	vdd_pnl1_reg: vdd_pnl1_reg {
		compatible = "regulator-fixed";
		regulator-name = "vdd_pnl1";
		regulator-min-microvolt = <3300000>;
		regulator-max-microvolt = <3300000>;
		enable-active-high;
		gpio = <&gpio TEGRA_GPIO(L, 4) GPIO_ACTIVE_HIGH>;
		vin-supply = <&sys_3v3_reg>;
		regulator-always-on;
		regulator-boot-on;
	};

	vdd_vid_reg: vdd_vid_reg {
		compatible = "regulator-fixed";
		regulator-name = "vddio_vid";
		regulator-min-microvolt = <5000000>;
		regulator-max-microvolt = <5000000>;
		enable-active-high;
		gpio = <&gpio TEGRA_GPIO(T, 0) GPIO_ACTIVE_HIGH>;
		gpio-open-drain;
		vin-supply = <&vdd_5v0_reg>;
		regulator-always-on;
		regulator-boot-on;
	};

	ddr_reg: ddr_reg {
		compatible = "regulator-fixed";
		regulator-name = "vdd_ddr";
		regulator-min-microvolt = <1500000>;
		regulator-max-microvolt = <1500000>;
		regulator-always-on;
		enable-active-high;
		gpio = <&pmic 7 GPIO_ACTIVE_HIGH>;
		regulator-boot-on;
	};

	sys_3v3_reg: sys_3v3_reg {
		compatible = "regulator-fixed";
		regulator-name = "sys_3v3";
		regulator-min-microvolt = <3300000>;
		regulator-max-microvolt = <3300000>;
		enable-active-high;
		gpio = <&pmic 6 GPIO_ACTIVE_HIGH>;
		regulator-always-on;
		regulator-boot-on;
	};

	usb1_vbus_reg: usb1_vbus_reg {
		compatible = "regulator-fixed";
		regulator-name = "usb1_vbus";
		regulator-min-microvolt = <5000000>;
		regulator-max-microvolt = <5000000>;
		enable-active-high;
		gpio = <&gpio TEGRA_GPIO(DD, 6) GPIO_ACTIVE_HIGH>;
		gpio-open-drain;
		vin-supply = <&vdd_5v0_reg>;
		regulator-always-on;
	};

	usb3_vbus_reg: usb3_vbus_reg {
		compatible = "regulator-fixed";
		regulator-name = "usb3_vbus";
		regulator-min-microvolt = <5000000>;
		regulator-max-microvolt = <5000000>;
		enable-active-high;
		gpio = <&gpio TEGRA_GPIO(DD, 4) GPIO_ACTIVE_HIGH>;
		gpio-open-drain;
		vin-supply = <&vdd_5v0_reg>;
	};

	vdd_5v0_reg: vdd_5v0_reg {
		compatible = "regulator-fixed";
		regulator-name = "5v0";
		regulator-min-microvolt = <5000000>;
		regulator-max-microvolt = <5000000>;
		enable-active-high;
		gpio = <&pmic 8 GPIO_ACTIVE_HIGH>;
		regulator-always-on;
		regulator-boot-on;
	};

	vdd_bl_reg: vdd_bl_reg {
		compatible = "regulator-fixed";
		regulator-name = "vdd_bl";
		regulator-min-microvolt = <5000000>;
		regulator-max-microvolt = <5000000>;
		enable-active-high;
		gpio = <&gpio TEGRA_GPIO(DD, 2) GPIO_ACTIVE_HIGH>;
		regulator-always-on;
		regulator-boot-on;
	};

	vdd_bl2_reg: vdd_bl2_reg {
		compatible = "regulator-fixed";
		regulator-name = "vdd_bl2";
		regulator-min-microvolt = <5000000>;
		regulator-max-microvolt = <5000000>;
		enable-active-high;
		gpio = <&gpio TEGRA_GPIO(DD, 0) GPIO_ACTIVE_HIGH>;
		regulator-always-on;
		regulator-boot-on;
	};

	vdd_smsc: vdd_smsc {
		compatible = "regulator-fixed";
		regulator-name = "vdd_smsc";
		regulator-min-microvolt = <3300000>;
		regulator-max-microvolt = <3300000>;
		enable-active-high;
		gpio = <&gpio TEGRA_GPIO(DD, 5) GPIO_ACTIVE_HIGH>;
		gpio-open-drain;
	};

/*	&gpio {
		lan_reset_n {
			gpio-hog;
			gpios = <&gpio TEGRA_GPIO(DD, 5) GPIO_ACTIVE_HIGH>;
			output-high;
			line-name = "LAN_RESET#";
		};
	};
*/

	hda@70030000 {
		status = "okay";
	};

	gpio-keys {
		power {
			gpios = <&gpio TEGRA_GPIO(V, 0) GPIO_ACTIVE_LOW>;
			debounce-interval = <10>;
			linux,code = <KEY_POWER>;
			wakeup-source;
		};
	};

	sdhci3_pwrseq: sdhci3_pwrseq {
		compatible = "mmc-pwrseq-simple";
		reset-gpios = <&gpio TEGRA_GPIO(D, 3) GPIO_ACTIVE_LOW>;
	};

/*	reboot-mode {
		mode-normal = <BOOT_NORMAL>;
		mode-recovery = <BOOT_RECOVERY>;
		mode-bootloader = <BOOT_FASTBOOT>;
		mode-loader = <BOOT_BL_DOWNLOAD>;
	};
*/
};
